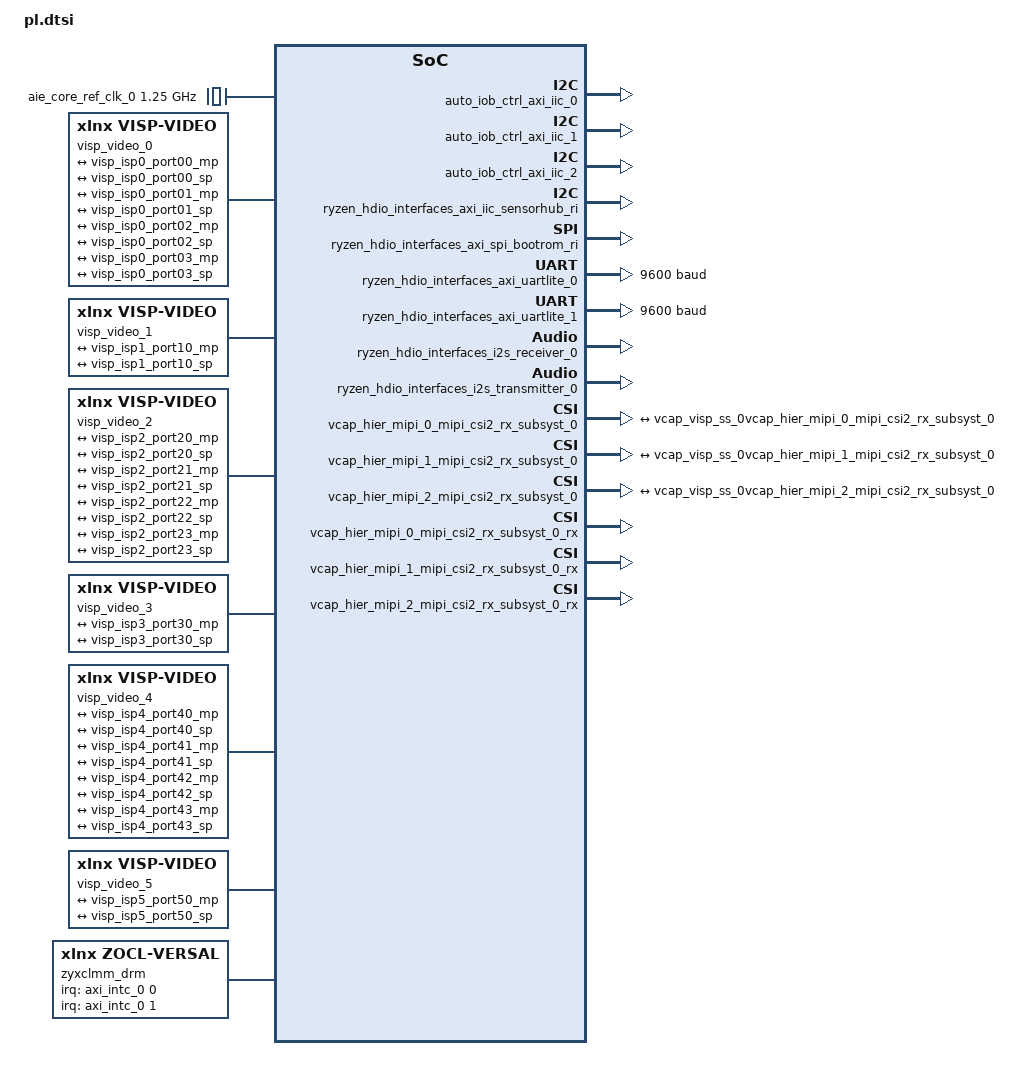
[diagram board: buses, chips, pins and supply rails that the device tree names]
/dts-v1/;
/plugin/;
&fpga {
	firmware-name = "vpl_gen_fixed_pld.pdi";
	misc_clk_3: misc_clk_3 {
		compatible = "fixed-clock";
		clock-frequency = <149998505>;
		#clock-cells = <0>;
	};
	misc_clk_4: misc_clk_4 {
		compatible = "fixed-clock";
		clock-frequency = <100000000>;
		#clock-cells = <0>;
	};
	misc_clk_2: misc_clk_2 {
		compatible = "fixed-clock";
		clock-frequency = <199998000>;
		#clock-cells = <0>;
	};
	misc_clk_6: misc_clk_6 {
		compatible = "fixed-clock";
		clock-frequency = <125000000>;
		#clock-cells = <0>;
	};
	misc_clk_0: misc_clk_0 {
		compatible = "fixed-clock";
		clock-frequency = <99999000>;
		#clock-cells = <0>;
	};
	misc_clk_5: misc_clk_5 {
		compatible = "fixed-clock";
		clock-frequency = <133332001>;
		#clock-cells = <0>;
	};
	misc_clk_1: misc_clk_1 {
		compatible = "fixed-clock";
		clock-frequency = <249997500>;
		#clock-cells = <0>;
	};
};

&amba {
	axi_intc_0: interrupt-controller@b01b0000 {
		#interrupt-cells = <2>;
		interrupts = < 0 143 4 >;
		xlnx,sense-of-irq-edge-type = "Rising";
		xlnx,edk-special = "INTR_CTRL";
		xlnx,kind-of-intr = <0xffe38>;
		xlnx,kind-of-edge = <0xffffffff>;
		xlnx,irq-is-level = <1>;
		xlnx,has-ivr = <1>;
		compatible = "xlnx,axi-intc-4.1" , "xlnx,xps-intc-1.00.a";
		xlnx,disable-synchronizers = <0>;
		xlnx,kind-of-lvl = <0xffffffff>;
		xlnx,ivar-reset-value = <0x10>;
		xlnx,irq-active = <0x1>;
		interrupt-parent = <&gic>;
		xlnx,en-cascade-mode = <0>;
		xlnx,ip-name = "axi_intc";
		xlnx,has-ilr = <0>;
		reg = <0x0 0xb01b0000 0x0 0x10000>;
		xlnx,addr-width = <0x20>;
		clocks = <&misc_clk_0>;
		xlnx,s-axi-aclk-freq-mhz = <0x5f5dd18>;
		xlnx,num-sw-intr = <0>;
		xlnx,irq-connection = <1>;
		xlnx,num-intr-inputs = <0x20>;
		xlnx,has-sie = <1>;
		xlnx,enable-async = <0>;
		xlnx,has-cie = <1>;
		xlnx,num-sync-ff = <2>;
		xlnx,edk-iptype = "PERIPHERAL";
		xlnx,mb-clk-not-connected = <1>;
		xlnx,has-ipr = <1>;
		xlnx,sense-of-irq-level-type = "Active_High";
		xlnx,cascade-master = <0>;
		xlnx,processor-clk-freq-mhz = <100>;
		xlnx,is-fast = <0x0>;
		clock-names = "s_axi_aclk";
		xlnx,has-fast = <0>;
		xlnx,ivar-rst-val = <0x10>;
		interrupt-controller;
		interrupt-names = "irq";
		xlnx,async-intr = <0xffcfffff>;
		xlnx,name = "axi_intc_0";
	};
	ai_engine_0: ai_engine@20000000000 {
		xlnx,num-mi-axi = <24>;
		compatible = "xlnx,ai-engine-2.0" , "xlnx,ai-engine-v2.0";
		xlnx,aie-ref-clk-freqmhz = <0x1fc9f08>;
		xlnx,num-mi-axis = <0>;
		xlnx,aie-max-freq = <1250>;
		xlnx,en-addr-virtualization = <0>;
		xlnx,aie-gen = /bits/ 8 <0x5>;
		xlnx,mem-rows = /bits/ 8 <1 1>;
		xlnx,mi-destid-pins;
		xlnx,ip-name = "ai_engine";
		#size-cells = <2>;
		xlnx,num-si-axi = <1>;
		xlnx,fast-pm-write;
		reg = <0x00000200 0x00000000 0x00000001 0x00000000>;
		clocks = <&aie_core_ref_clk_0>;
		xlnx,num-noc-axis-clks = <0>;
		ranges;
		xlnx,num-clks = <0>;
		xlnx,partition-enabled = <0>;
		#address-cells = <2>;
		xlnx,num-si-axis = <0>;
		xlnx,name-mi-axi = "M00_AXI";
		xlnx,num-column = <1>;
		xlnx,aie-core-ref-ctrl-freqmhz = <1250>;
		xlnx,clk-names = "aclk0";
		xlnx,fast-dm-write;
		xlnx,edk-iptype = "PERIPHERAL";
		xlnx,selected-nsu = <0>;
		clock-names = "aclk0";
		power-domains = <&versal2_firmware 0x18800000>;
		xlnx,num-trig-in = <0>;
		xlnx,en-ext-rst = <1>;
		xlnx,num-trig-out = <0>;
		xlnx,core-rows = /bits/ 8 <2 4>;
		xlnx,shim-rows = /bits/ 8 <0 1>;
		xlnx,name-si-axi = "S00_AXI";
		xlnx,start-column = <0>;
		xlnx,name = "ai_engine_0";
		xlnx,aie-site = "AIE2PS";
		aie_aperture_0: aie_aperture@20000000000 {
			xlnx,device-name = <0>;
			interrupt-parent = <&gic>;
			interrupts = <0x0 0xce 0x4>, <0x0 0xcf 0x4>, <0x0 0xd0 0x4>;
			#address-cells = <2>;
			power-domains = <&versal2_firmware 0x18800000>;
			xlnx,node-id = <0x18800000>;
			#size-cells = <2>;
			interrupt-names = "interrupt1" , "interrupt2" , "interrupt3";
			reg = <0x00000200 0x00000000 0x00000001 0x00000000>;
			xlnx,columns = < 0 24 >;
		};
	};
	auto_iob_ctrl_axi_gpio_0: gpio@b0130000 {
		xlnx,gpio-board-interface = "Custom";
		compatible = "xlnx,axi-gpio-2.0" , "xlnx,xps-gpio-1.00.a";
		xlnx,all-outputs = <0>;
		#gpio-cells = <2>;
		xlnx,gpio-width = <24>;
		xlnx,dout-default = <0x24042>;
		xlnx,is-dual = <0>;
		xlnx,ip-name = "axi_gpio";
		xlnx,tri-default-2 = <0xffffffff>;
		reg = <0x0 0xb0130000 0x0 0x10000>;
		xlnx,all-inputs-2 = <0>;
		clocks = <&misc_clk_0>;
		xlnx,all-outputs-2 = <0>;
		gpio-controller;
		xlnx,interrupt-present = <0>;
		xlnx,gpio2-board-interface = "Custom";
		xlnx,edk-iptype = "PERIPHERAL";
		xlnx,dout-default-2 = <0x0>;
		xlnx,gpio2-width = <32>;
		clock-names = "s_axi_aclk";
		xlnx,tri-default = <0xf00>;
		xlnx,name = "auto_iob_ctrl_axi_gpio_0";
		xlnx,all-inputs = <0>;
	};
	auto_iob_ctrl_axi_gpio_1: gpio@b0140000 {
		xlnx,gpio-board-interface = "Custom";
		compatible = "xlnx,axi-gpio-2.0" , "xlnx,xps-gpio-1.00.a";
		xlnx,all-outputs = <0>;
		#gpio-cells = <2>;
		xlnx,gpio-width = <5>;
		xlnx,dout-default = <0x0>;
		xlnx,is-dual = <0>;
		xlnx,ip-name = "axi_gpio";
		xlnx,tri-default-2 = <0xffffffff>;
		reg = <0x0 0xb0140000 0x0 0x10000>;
		xlnx,all-inputs-2 = <0>;
		clocks = <&misc_clk_0>;
		xlnx,all-outputs-2 = <0>;
		gpio-controller;
		xlnx,interrupt-present = <0>;
		xlnx,gpio2-board-interface = "Custom";
		xlnx,edk-iptype = "PERIPHERAL";
		xlnx,dout-default-2 = <0x0>;
		xlnx,gpio2-width = <32>;
		clock-names = "s_axi_aclk";
		xlnx,tri-default = <0xffffffff>;
		xlnx,name = "auto_iob_ctrl_axi_gpio_1";
		xlnx,all-inputs = <0>;
	};
	auto_iob_ctrl_axi_gpio_2: gpio@b0150000 {
		xlnx,gpio-board-interface = "Custom";
		compatible = "xlnx,axi-gpio-2.0" , "xlnx,xps-gpio-1.00.a";
		xlnx,all-outputs = <0>;
		#gpio-cells = <2>;
		xlnx,gpio-width = <5>;
		xlnx,dout-default = <0x0>;
		xlnx,is-dual = <0>;
		xlnx,ip-name = "axi_gpio";
		xlnx,tri-default-2 = <0xffffffff>;
		reg = <0x0 0xb0150000 0x0 0x10000>;
		xlnx,all-inputs-2 = <0>;
		clocks = <&misc_clk_0>;
		xlnx,all-outputs-2 = <0>;
		gpio-controller;
		xlnx,interrupt-present = <0>;
		xlnx,gpio2-board-interface = "Custom";
		xlnx,edk-iptype = "PERIPHERAL";
		xlnx,dout-default-2 = <0x0>;
		xlnx,gpio2-width = <32>;
		clock-names = "s_axi_aclk";
		xlnx,tri-default = <0xffffffff>;
		xlnx,name = "auto_iob_ctrl_axi_gpio_2";
		xlnx,all-inputs = <0>;
	};
	auto_iob_ctrl_axi_gpio_3: gpio@b0160000 {
		xlnx,gpio-board-interface = "Custom";
		compatible = "xlnx,axi-gpio-2.0" , "xlnx,xps-gpio-1.00.a";
		xlnx,all-outputs = <0>;
		#gpio-cells = <2>;
		xlnx,gpio-width = <6>;
		xlnx,dout-default = <0x0>;
		xlnx,is-dual = <0>;
		xlnx,ip-name = "axi_gpio";
		xlnx,tri-default-2 = <0xffffffff>;
		reg = <0x0 0xb0160000 0x0 0x10000>;
		xlnx,all-inputs-2 = <0>;
		clocks = <&misc_clk_0>;
		xlnx,all-outputs-2 = <0>;
		gpio-controller;
		xlnx,interrupt-present = <0>;
		xlnx,gpio2-board-interface = "Custom";
		xlnx,edk-iptype = "PERIPHERAL";
		xlnx,dout-default-2 = <0x0>;
		xlnx,gpio2-width = <32>;
		clock-names = "s_axi_aclk";
		xlnx,tri-default = <0xffffffff>;
		xlnx,name = "auto_iob_ctrl_axi_gpio_3";
		xlnx,all-inputs = <0>;
	};
	auto_iob_ctrl_axi_iic_0: i2c@80000000 {
		interrupts = < 0 90 4 >;
		xlnx,iic-freq-khz = <100>;
		compatible = "xlnx,axi-iic-2.1" , "xlnx,xps-iic-2.00.a";
		xlnx,scl-inertial-delay = <0>;
		interrupt-parent = <&gic>;
		xlnx,ip-name = "axi_iic";
		xlnx,disable-setup-violation-check = <0>;
		reg = <0x0 0x80000000 0x0 0x10000>;
		clocks = <&misc_clk_0>;
		xlnx,gpo-width = <1>;
		xlnx,edk-iptype = "PERIPHERAL";
		xlnx,static-timing-reg-width = <0>;
		xlnx,sda-level = <1>;
		clock-names = "s_axi_aclk";
		xlnx,ten-bit-adr = <0>;
		xlnx,default-value = <0x0>;
		interrupt-names = "iic2intc_irpt";
		xlnx,iic-board-interface = "Custom";
		xlnx,timing-reg-width = <32>;
		xlnx,iic-freq = <100000>;
		xlnx,smbus-pmbus-host = <0>;
		xlnx,name = "auto_iob_ctrl_axi_iic_0";
		xlnx,axi-aclk-freq-mhz = <0x5f5dd18>;
		xlnx,sda-inertial-delay = <0>;
	};
	auto_iob_ctrl_axi_iic_1: i2c@80010000 {
		interrupts = < 0 88 4 >;
		xlnx,iic-freq-khz = <100>;
		compatible = "xlnx,axi-iic-2.1" , "xlnx,xps-iic-2.00.a";
		xlnx,scl-inertial-delay = <0>;
		interrupt-parent = <&gic>;
		xlnx,ip-name = "axi_iic";
		xlnx,disable-setup-violation-check = <0>;
		reg = <0x0 0x80010000 0x0 0x10000>;
		clocks = <&misc_clk_0>;
		xlnx,gpo-width = <1>;
		xlnx,edk-iptype = "PERIPHERAL";
		xlnx,static-timing-reg-width = <0>;
		xlnx,sda-level = <1>;
		clock-names = "s_axi_aclk";
		xlnx,ten-bit-adr = <0>;
		xlnx,default-value = <0x0>;
		interrupt-names = "iic2intc_irpt";
		xlnx,iic-board-interface = "Custom";
		xlnx,timing-reg-width = <32>;
		xlnx,iic-freq = <100000>;
		xlnx,smbus-pmbus-host = <0>;
		xlnx,name = "auto_iob_ctrl_axi_iic_1";
		xlnx,axi-aclk-freq-mhz = <0x5f5dd18>;
		xlnx,sda-inertial-delay = <0>;
	};
	auto_iob_ctrl_axi_iic_2: i2c@80020000 {
		interrupts = < 0 89 4 >;
		xlnx,iic-freq-khz = <100>;
		compatible = "xlnx,axi-iic-2.1" , "xlnx,xps-iic-2.00.a";
		xlnx,scl-inertial-delay = <0>;
		interrupt-parent = <&gic>;
		xlnx,ip-name = "axi_iic";
		xlnx,disable-setup-violation-check = <0>;
		reg = <0x0 0x80020000 0x0 0x10000>;
		clocks = <&misc_clk_0>;
		xlnx,gpo-width = <1>;
		xlnx,edk-iptype = "PERIPHERAL";
		xlnx,static-timing-reg-width = <0>;
		xlnx,sda-level = <1>;
		clock-names = "s_axi_aclk";
		xlnx,ten-bit-adr = <0>;
		xlnx,default-value = <0x0>;
		interrupt-names = "iic2intc_irpt";
		xlnx,iic-board-interface = "Custom";
		xlnx,timing-reg-width = <32>;
		xlnx,iic-freq = <100000>;
		xlnx,smbus-pmbus-host = <0>;
		xlnx,name = "auto_iob_ctrl_axi_iic_2";
		xlnx,axi-aclk-freq-mhz = <0x5f5dd18>;
		xlnx,sda-inertial-delay = <0>;
	};
	axi_bram_ctrl_mdb5_v4l2: axi_bram_ctrl_mdb5_v4l2@80000008000 {
		xlnx,protocol = "AXI4";
		xlnx,edk-special = "BRAM_CTRL";
		compatible = "xlnx,axi-bram-ctrl-4.1" , "xlnx,axi-bram-ctrl";
		xlnx,ecc-onoff-reset-value = <0>;
		xlnx,ecc-type = <0>;
		xlnx,rd-cmd-optimization = <0>;
		xlnx,memory-depth = <2048>;
		xlnx,use-ecc = <0>;
		xlnx,fault-inject = <0>;
		xlnx,ip-name = "axi_bram_ctrl";
		reg = <0x00000800 0x00008000 0x0 0x2000>;
		xlnx,bmg-instance = "EXTERNAL";
		clocks = <&misc_clk_1>;
		xlnx,s-axi-ctrl-addr-width = <32>;
		xlnx,read-latency = <1>;
		xlnx,id-width = <0>;
		xlnx,s-axi-supports-narrow-burst = <0>;
		xlnx,supports-narrow-burst = <0>;
		xlnx,single-port-bram = <1>;
		xlnx,ecc = <0>;
		xlnx,edk-iptype = "PERIPHERAL";
		clock-names = "s_axi_aclk";
		xlnx,data-width = <32>;
		xlnx,bram-addr-width = <11>;
		xlnx,bram-inst-mode = "EXTERNAL";
		xlnx,s-axi-ctrl-data-width = <32>;
		xlnx,mem-depth = <2048>;
		xlnx,s-axi-id-width = <1>;
		xlnx,name = "axi_bram_ctrl_mdb5_v4l2";
	};
	axi_gpio_rst: gpio@b01a0000 {
		xlnx,gpio-board-interface = "Custom";
		compatible = "xlnx,axi-gpio-2.0" , "xlnx,xps-gpio-1.00.a";
		xlnx,all-outputs = <1>;
		#gpio-cells = <2>;
		xlnx,gpio-width = <32>;
		xlnx,dout-default = <0xffffffff>;
		xlnx,is-dual = <0>;
		xlnx,ip-name = "axi_gpio";
		xlnx,tri-default-2 = <0xffffffff>;
		reg = <0x0 0xb01a0000 0x0 0x10000>;
		xlnx,all-inputs-2 = <0>;
		clocks = <&misc_clk_0>;
		xlnx,all-outputs-2 = <0>;
		gpio-controller;
		xlnx,interrupt-present = <0>;
		xlnx,gpio2-board-interface = "Custom";
		xlnx,edk-iptype = "PERIPHERAL";
		xlnx,dout-default-2 = <0x0>;
		xlnx,gpio2-width = <32>;
		clock-names = "s_axi_aclk";
		xlnx,tri-default = <0xffffffff>;
		xlnx,name = "axi_gpio_rst";
		xlnx,all-inputs = <0>;
	};
	messaging_axi_bram_ctrl_0: messaging_axi_bram_ctrl_0@80100000000 {
		xlnx,protocol = "AXI4";
		xlnx,edk-special = "BRAM_CTRL";
		compatible = "xlnx,axi-bram-ctrl-4.1" , "xlnx,axi-bram-ctrl";
		xlnx,ecc-onoff-reset-value = <0>;
		xlnx,ecc-type = <0>;
		xlnx,rd-cmd-optimization = <0>;
		xlnx,memory-depth = <2048>;
		xlnx,use-ecc = <0>;
		xlnx,fault-inject = <0>;
		xlnx,ip-name = "axi_bram_ctrl";
		reg = <0x00000801 0x00000000 0x0 0x2000>;
		xlnx,bmg-instance = "EXTERNAL";
		clocks = <&misc_clk_0>;
		xlnx,s-axi-ctrl-addr-width = <32>;
		xlnx,read-latency = <1>;
		xlnx,id-width = <0>;
		xlnx,s-axi-supports-narrow-burst = <0>;
		xlnx,supports-narrow-burst = <0>;
		xlnx,single-port-bram = <1>;
		xlnx,ecc = <0>;
		xlnx,edk-iptype = "PERIPHERAL";
		clock-names = "s_axi_aclk";
		xlnx,data-width = <32>;
		xlnx,bram-addr-width = <11>;
		xlnx,bram-inst-mode = "EXTERNAL";
		xlnx,s-axi-ctrl-data-width = <32>;
		xlnx,mem-depth = <2048>;
		xlnx,s-axi-id-width = <1>;
		xlnx,name = "messaging_axi_bram_ctrl_0";
	};
	messaging_axi_bram_ctrl_1: messaging_axi_bram_ctrl_1@80100002000 {
		xlnx,protocol = "AXI4";
		xlnx,edk-special = "BRAM_CTRL";
		compatible = "xlnx,axi-bram-ctrl-4.1" , "xlnx,axi-bram-ctrl";
		xlnx,ecc-onoff-reset-value = <0>;
		xlnx,ecc-type = <0>;
		xlnx,rd-cmd-optimization = <0>;
		xlnx,memory-depth = <2048>;
		xlnx,use-ecc = <0>;
		xlnx,fault-inject = <0>;
		xlnx,ip-name = "axi_bram_ctrl";
		reg = <0x00000801 0x00002000 0x0 0x2000>;
		xlnx,bmg-instance = "EXTERNAL";
		clocks = <&misc_clk_0>;
		xlnx,s-axi-ctrl-addr-width = <32>;
		xlnx,read-latency = <1>;
		xlnx,id-width = <0>;
		xlnx,s-axi-supports-narrow-burst = <0>;
		xlnx,supports-narrow-burst = <0>;
		xlnx,single-port-bram = <1>;
		xlnx,ecc = <0>;
		xlnx,edk-iptype = "PERIPHERAL";
		clock-names = "s_axi_aclk";
		xlnx,data-width = <32>;
		xlnx,bram-addr-width = <11>;
		xlnx,bram-inst-mode = "EXTERNAL";
		xlnx,s-axi-ctrl-data-width = <32>;
		xlnx,mem-depth = <2048>;
		xlnx,s-axi-id-width = <1>;
		xlnx,name = "messaging_axi_bram_ctrl_1";
	};
	messaging_axi_gpio_0: gpio@80100005000 {
		xlnx,gpio-board-interface = "Custom";
		compatible = "xlnx,axi-gpio-2.0" , "xlnx,xps-gpio-1.00.a";
		xlnx,all-outputs = <1>;
		#gpio-cells = <2>;
		xlnx,gpio-width = <2>;
		xlnx,dout-default = <0x0>;
		xlnx,is-dual = <0>;
		xlnx,ip-name = "axi_gpio";
		xlnx,tri-default-2 = <0xffffffff>;
		reg = <0x00000801 0x00005000 0x0 0x1000>;
		xlnx,all-inputs-2 = <0>;
		clocks = <&misc_clk_0>;
		xlnx,all-outputs-2 = <0>;
		gpio-controller;
		xlnx,interrupt-present = <0>;
		xlnx,gpio2-board-interface = "Custom";
		xlnx,edk-iptype = "PERIPHERAL";
		xlnx,dout-default-2 = <0x0>;
		xlnx,gpio2-width = <32>;
		clock-names = "s_axi_aclk";
		xlnx,tri-default = <0xffffffff>;
		xlnx,name = "messaging_axi_gpio_0";
		xlnx,all-inputs = <0>;
	};
	messaging_axi_gpio_1: gpio@80100004000 {
		xlnx,gpio-board-interface = "Custom";
		compatible = "xlnx,axi-gpio-2.0" , "xlnx,xps-gpio-1.00.a";
		xlnx,all-outputs = <1>;
		#gpio-cells = <2>;
		xlnx,gpio-width = <2>;
		xlnx,dout-default = <0x0>;
		xlnx,is-dual = <0>;
		xlnx,ip-name = "axi_gpio";
		xlnx,tri-default-2 = <0xffffffff>;
		reg = <0x00000801 0x00004000 0x0 0x1000>;
		xlnx,all-inputs-2 = <0>;
		clocks = <&misc_clk_0>;
		xlnx,all-outputs-2 = <0>;
		gpio-controller;
		xlnx,interrupt-present = <0>;
		xlnx,gpio2-board-interface = "Custom";
		xlnx,edk-iptype = "PERIPHERAL";
		xlnx,dout-default-2 = <0x0>;
		xlnx,gpio2-width = <32>;
		clock-names = "s_axi_aclk";
		xlnx,tri-default = <0xffffffff>;
		xlnx,name = "messaging_axi_gpio_1";
		xlnx,all-inputs = <0>;
	};
	ryzen_hdio_interfaces_axi_gpio_0: gpio@b01c0000 {
		xlnx,gpio-board-interface = "Custom";
		compatible = "xlnx,axi-gpio-2.0" , "xlnx,xps-gpio-1.00.a";
		xlnx,all-outputs = <0>;
		#gpio-cells = <2>;
		xlnx,gpio-width = <2>;
		xlnx,dout-default = <0x0>;
		xlnx,is-dual = <0>;
		xlnx,ip-name = "axi_gpio";
		xlnx,tri-default-2 = <0xffffffff>;
		reg = <0x0 0xb01c0000 0x0 0x10000>;
		xlnx,all-inputs-2 = <0>;
		clocks = <&misc_clk_0>;
		xlnx,all-outputs-2 = <0>;
		gpio-controller;
		xlnx,interrupt-present = <0>;
		xlnx,gpio2-board-interface = "Custom";
		xlnx,edk-iptype = "PERIPHERAL";
		xlnx,dout-default-2 = <0x0>;
		xlnx,gpio2-width = <32>;
		clock-names = "s_axi_aclk";
		xlnx,tri-default = <0xffffffff>;
		xlnx,name = "ryzen_hdio_interfaces_axi_gpio_0";
		xlnx,all-inputs = <0>;
	};
	ryzen_hdio_interfaces_axi_gpio_bootrom_ri: gpio@b01d0000 {
		xlnx,gpio-board-interface = "Custom";
		compatible = "xlnx,axi-gpio-2.0" , "xlnx,xps-gpio-1.00.a";
		xlnx,all-outputs = <0>;
		#gpio-cells = <2>;
		xlnx,gpio-width = <1>;
		xlnx,dout-default = <0x0>;
		xlnx,is-dual = <0>;
		xlnx,ip-name = "axi_gpio";
		xlnx,tri-default-2 = <0xffffffff>;
		reg = <0x0 0xb01d0000 0x0 0x10000>;
		xlnx,all-inputs-2 = <0>;
		clocks = <&misc_clk_0>;
		xlnx,all-outputs-2 = <0>;
		gpio-controller;
		xlnx,interrupt-present = <0>;
		xlnx,gpio2-board-interface = "Custom";
		xlnx,edk-iptype = "PERIPHERAL";
		xlnx,dout-default-2 = <0x0>;
		xlnx,gpio2-width = <32>;
		clock-names = "s_axi_aclk";
		xlnx,tri-default = <0xffffffff>;
		xlnx,name = "ryzen_hdio_interfaces_axi_gpio_bootrom_ri";
		xlnx,all-inputs = <0>;
	};
	ryzen_hdio_interfaces_axi_gpio_sensorhub_ri: gpio@b01e0000 {
		xlnx,gpio-board-interface = "Custom";
		compatible = "xlnx,axi-gpio-2.0" , "xlnx,xps-gpio-1.00.a";
		xlnx,all-outputs = <0>;
		#gpio-cells = <2>;
		xlnx,gpio-width = <1>;
		xlnx,dout-default = <0x0>;
		xlnx,is-dual = <0>;
		xlnx,ip-name = "axi_gpio";
		xlnx,tri-default-2 = <0xffffffff>;
		reg = <0x0 0xb01e0000 0x0 0x10000>;
		xlnx,all-inputs-2 = <0>;
		clocks = <&misc_clk_0>;
		xlnx,all-outputs-2 = <0>;
		gpio-controller;
		xlnx,interrupt-present = <0>;
		xlnx,gpio2-board-interface = "Custom";
		xlnx,edk-iptype = "PERIPHERAL";
		xlnx,dout-default-2 = <0x0>;
		xlnx,gpio2-width = <32>;
		clock-names = "s_axi_aclk";
		xlnx,tri-default = <0xffffffff>;
		xlnx,name = "ryzen_hdio_interfaces_axi_gpio_sensorhub_ri";
		xlnx,all-inputs = <0>;
	};
	ryzen_hdio_interfaces_axi_iic_sensorhub_ri: i2c@b01f0000 {
		xlnx,iic-freq-khz = <100>;
		compatible = "xlnx,axi-iic-2.1" , "xlnx,xps-iic-2.00.a";
		xlnx,scl-inertial-delay = <0>;
		xlnx,ip-name = "axi_iic";
		xlnx,disable-setup-violation-check = <0>;
		reg = <0x0 0xb01f0000 0x0 0x10000>;
		clocks = <&misc_clk_0>;
		xlnx,gpo-width = <1>;
		xlnx,edk-iptype = "PERIPHERAL";
		xlnx,static-timing-reg-width = <0>;
		xlnx,sda-level = <1>;
		clock-names = "s_axi_aclk";
		xlnx,ten-bit-adr = <0>;
		xlnx,default-value = <0x0>;
		xlnx,iic-board-interface = "Custom";
		xlnx,timing-reg-width = <32>;
		xlnx,iic-freq = <100000>;
		xlnx,smbus-pmbus-host = <0>;
		xlnx,name = "ryzen_hdio_interfaces_axi_iic_sensorhub_ri";
		xlnx,axi-aclk-freq-mhz = <0x5f5dd18>;
		xlnx,sda-inertial-delay = <0>;
	};
	ryzen_hdio_interfaces_axi_spi_bootrom_ri: axi_quad_spi@b0210000 {
		xlnx,select-xpm = <0>;
		compatible = "xlnx,axi-quad-spi-3.2" , "xlnx,xps-spi-2.00.a";
		xlnx,lsb-stup = <0>;
		xlnx,num-ss-bits = <0x1>;
		xlnx,hasfifos = <1>;
		xlnx,xip-mode = <0>;
		xlnx,use-startup-ext = <0>;
		xlnx,s-axi4-addr-width = <24>;
		xlnx,byte-level-interrupt-en = <0>;
		num-cs = <0x1>;
		xlnx,xip-perf-mode = <1>;
		xlnx,sck-ratio = <16>;
		xlnx,s-axi4-id-width = <4>;
		fifo-size = <16>;
		xlnx,multiples16 = <1>;
		xlnx,master-mode = <1>;
		xlnx,shared-startup = <0>;
		xlnx,ip-name = "axi_quad_spi";
		xlnx,qspi-board-interface = "Custom";
		reg = <0x0 0xb0210000 0x0 0x10000>;
		xlnx,dual-quad-mode = <0>;
		xlnx,new-seq-en = <1>;
		bits-per-word = <8>;
		clocks = <&misc_clk_0>, <&misc_clk_0>;
		xlnx,num-transfer-bits = <8>;
		xlnx,spi-memory = <1>;
		xlnx,s-axi4-data-width = <32>;
		xlnx,edk-iptype = "PERIPHERAL";
		xlnx,slaveonly = <0>;
		xlnx,use-startup-int = <0>;
		xlnx,use-startup = <0>;
		xlnx,type-of-axi4-interface = <0>;
		xlnx,async-clk = <0>;
		xlnx,spi-mode = <0>;
		xlnx,sck-ratio1 = <1>;
		xlnx,fifo-depth = <16>;
		clock-names = "ext_spi_clk" , "s_axi_aclk";
		xlnx,uc-family = <0>;
		xlnx,spi-mem-addr-bits = <24>;
		xlnx,axi-interface = <0>;
		xlnx,Axi4-address = <0>;
		xlnx,fifo-included = <1>;
		xlnx,sub-family = "versal";
		xlnx,name = "ryzen_hdio_interfaces_axi_spi_bootrom_ri";
	};
	ryzen_hdio_interfaces_axi_uartlite_0: serial@b0220000 {
		compatible = "xlnx,axi-uartlite-2.0" , "xlnx,xps-uartlite-1.00.a";
		xlnx,uartlite-board-interface = "Custom";
		xlnx,s-axi-aclk-freq-hz-d = <0x5f5dd18>;
		xlnx,ip-name = "axi_uartlite";
		reg = <0x0 0xb0220000 0x0 0x10000>;
		xlnx,baudrate = <9600>;
		clocks = <&misc_clk_0>;
		current-speed = <9600>;
		xlnx,use-parity = <0>;
		xlnx,edk-iptype = "PERIPHERAL";
		xlnx,odd-parity = <0>;
		clock-names = "s_axi_aclk";
		xlnx,name = "ryzen_hdio_interfaces_axi_uartlite_0";
		xlnx,data-bits = <8>;
		xlnx,parity = "No_Parity";
	};
	ryzen_hdio_interfaces_axi_uartlite_1: serial@b0230000 {
		compatible = "xlnx,axi-uartlite-2.0" , "xlnx,xps-uartlite-1.00.a";
		xlnx,uartlite-board-interface = "Custom";
		xlnx,s-axi-aclk-freq-hz-d = <0x5f5dd18>;
		xlnx,ip-name = "axi_uartlite";
		reg = <0x0 0xb0230000 0x0 0x10000>;
		xlnx,baudrate = <9600>;
		clocks = <&misc_clk_0>;
		current-speed = <9600>;
		xlnx,use-parity = <0>;
		xlnx,edk-iptype = "PERIPHERAL";
		xlnx,odd-parity = <0>;
		clock-names = "s_axi_aclk";
		xlnx,name = "ryzen_hdio_interfaces_axi_uartlite_1";
		xlnx,data-bits = <8>;
		xlnx,parity = "No_Parity";
	};
	ryzen_hdio_interfaces_i2s_receiver_0: i2s_receiver@b0010000 {
		aud_mclk = <99999000>;
		interrupts = < 11 2 >;
		compatible = "xlnx,i2s-receiver-1.0" , "xlnx,i2s-receiver-1.0";
		xlnx,dwidth = <0x18>;
		xlnx,depth = <0x80>;
		interrupt-parent = <&axi_intc_0>;
		xlnx,ip-name = "i2s_receiver";
		reg = <0x0 0xb0010000 0x0 0x10000>;
		clocks = <&misc_clk_0>, <&misc_clk_0>, <&misc_clk_0>;
		xlnx,num-channels = <0x1>;
		xlnx,i2srx-board-interface = "Custom";
		xlnx,edk-iptype = "PERIPHERAL";
		xlnx,is-master = <1>;
		clock-names = "aud_mclk" , "m_axis_aud_aclk" , "s_axi_ctrl_aclk";
		xlnx,32bit-lr = <0>;
		interrupt-names = "irq";
		xlnx,name = "ryzen_hdio_interfaces_i2s_receiver_0";
	};
	ryzen_hdio_interfaces_i2s_transmitter_0: i2s_transmitter@b0020000 {
		aud_mclk = <99999000>;
		interrupts = < 12 2 >;
		compatible = "xlnx,i2s-transmitter-1.0" , "xlnx,i2s-transmitter-1.0";
		xlnx,dwidth = <0x18>;
		xlnx,depth = <0x80>;
		interrupt-parent = <&axi_intc_0>;
		xlnx,ip-name = "i2s_transmitter";
		reg = <0x0 0xb0020000 0x0 0x10000>;
		clocks = <&misc_clk_0>, <&misc_clk_0>, <&misc_clk_0>;
		xlnx,num-channels = <0x1>;
		xlnx,edk-iptype = "PERIPHERAL";
		xlnx,is-master = <1>;
		xlnx,i2stx-board-interface = "Custom";
		clock-names = "aud_mclk" , "s_axi_ctrl_aclk" , "s_axis_aud_aclk";
		xlnx,32bit-lr = <0>;
		interrupt-names = "irq";
		xlnx,name = "ryzen_hdio_interfaces_i2s_transmitter_0";
	};
	vcap_hier_mipi_0_mipi_csi2_rx_subsyst_0: mipi_csi2_rx_subsystem@b0040000 {
		xlnx,data-lane2-byte = "All_Byte";
		xlnx,dpy-en-reg-if = <1>;
		xlnx,cmn-vc = <4>;
		xlnx,dphy-lanes = <4>;
		xlnx,ip-name = "mipi_csi2_rx_subsystem";
		reg = <0x0 0xb0040000 0x0 0x2000>;
		xlnx,vfb-tu-width = <1>;
		xlnx,ppc = <4>;
		xlnx,csi-buf-depth = <4096>;
		xlnx,exdes-fmc = "LI-IMX274MIPI-FMC , V1.0 , Single , Sensor";
		xlnx,supportlevel = <1>;
		xlnx,clk-lane-io-loc-name = "None";
		xlnx,max-lanes = <4>;
		xlnx,is-versal;
		xlnx,cmn-inc-iic = <0>;
		xlnx,clk-lane-io-loc = "None";
		xlnx,esc-timeout = <25600>;
		interrupt-names = "csirxss_csi_irq";
		xlnx,cmn-inc-vfb;
		xlnx,axis-tuser-width = <96>;
		compatible = "xlnx,mipi-csi2-rx-subsystem-6.0" , "xlnx,mipi-csi2-rx-subsystem-5.0";
		xlnx,en-active-lanes;
		xlnx,idly-tap = <1>;
		dphy-present = <0>;
		xlnx,cmn-num-pixels = <4>;
		xlnx,cmn-proj-family = <0>;
		xlnx,csi2rx-dbg = <0>;
		xlnx,fifo-rd-en-control;
		xlnx,vfb;
		interrupt-parent = <&axi_intc_0>;
		xlnx,data-lane1-io-loc-name = "None";
		xlnx,hs-timeout = <65541>;
		xlnx,data-lane3-io-loc-name = "None";
		xlnx,ext-mmcm = <0>;
		xlnx,data-lane1-byte = "All_Byte";
		xlnx,master-riu;
		xlnx,cal-mode = "NONE";
		xlnx,csi-filter-userdatatype;
		rxphy-connected = <&vcap_hier_mipi_0_mipi_csi2_rx_subsyst_0_phy>;
		xlnx,mipi-rx-phy-mode = <1>;
		xlnx,data-lane0-io-position = <2>;
		xlnx,exdes-board = "VEK280";
		xlnx,data-lane2-io-position = <6>;
		xlnx,vc = <4>;
		xlnx,en-vcx = <0>;
		xlnx,name = "vcap_hier_mipi_0_mipi_csi2_rx_subsyst_0";
		xlnx,csi-emb-non-img = <0>;
		interrupts = < 1 2 >;
		xlnx,dphyrx-board-interface = "Custom";
		xlnx,data-lane3-io-loc = "None";
		xlnx,clock-mask = <39>;
		xlnx,hs-settle-ns = <25>;
		clocks = <&misc_clk_2>, <&misc_clk_3>, <&misc_clk_3>;
		xlnx,data-lane2-io-loc = "None";
		xlnx,mipi-slv-int = <0>;
		xlnx,is-ksb;
		xlnx,cmn-fifo-rd-en-cntrl;
		xlnx,data-lane3-byte = "All_Byte";
		xlnx,stretch-line-rate = <4500>;
		xlnx,phy-mode = "DPHY";
		xlnx,axis-tdest-width = <4>;
		xlnx,en-csi-v2 = <0>;
		xlnx,edk-iptype = "PERIPHERAL";
		xlnx,init = <100000>;
		xlnx,cmn-pxl-format = <0x2c>;
		xlnx,int-qor-check = <0>;
		clock-names = "dphy_clk_200M" , "lite_aclk" , "video_aclk";
		xlnx,data-lane1-io-loc = "None";
		xlnx,data-lane0-byte = "All_Byte";
		xlnx,ooc-vid-clk = <0x65b710>;
		csirx-present = <1>;
		xlnx,yuv420-buf-dpth = <128>;
		xlnx,hp-io-bank-selection = <64>;
		xlnx,idly-group-name = "mipi_csi2rx_idly_group";
		xlnx,lprx-disable-extport = <0>;
		csirx-connected = <&vcap_hier_mipi_0_mipi_csi2_rx_subsyst_0_rx>;
		xlnx,highaddr = <0xb0041fff>;
		xlnx,cmn-num-lanes = <4>;
		xlnx,exdes-config = "MIPI_Video_Pipe_Camera_to_Display";
		xlnx,exdesboard-version = <2>;
		xlnx,dphy-preset = "CSI2RX_XLNX";
		xlnx,data-lane0-io-loc-name = "None";
		xlnx,csi-pxl-format = <0x2c>;
		xlnx,clk-lane-io-position = <0>;
		xlnx,data-lane2-io-loc-name = "None";
		xlnx,data-lane0-io-loc = "None";
		xlnx,inc-phy;
		xlnx,hs-line-rate = <800>;
		rxphy-present = <1>;
		xlnx,dpy-line-rate = <1500>;
		xlnx,csi-en-activelanes;
		xlnx,sprt-isp-bridge;
		xlnx,csi-en-crc = <1>;
		xlnx,axis-tdata-width = <32>;
		xlnx,csi-controller-reg-if;
		xlnx,data-lane1-io-position = <4>;
		xlnx,dphy-mode = "SLAVE";
		xlnx,data-lane3-io-position = <8>;
		mipi_csi_portsvcap_hier_mipi_0_mipi_csi2_rx_subsyst_0: ports {
			#address-cells = <1>;
			#size-cells = <0>;
			mipi_csi_port1vcap_hier_mipi_0_mipi_csi2_rx_subsyst_0: port@1 {
				xlnx,video-width = <8>;
				reg = <1>;
				xlnx,video-format = <12>;
				xlnx,cfa-pattern = "rggb";
				mipi_csirx_outvcap_hier_mipi_0_mipi_csi2_rx_subsyst_0: endpoint {
					remote-endpoint = <&vcap_visp_ss_0vcap_hier_mipi_0_mipi_csi2_rx_subsyst_0>;
				};
			};
			mipi_csi_port0vcap_hier_mipi_0_mipi_csi2_rx_subsyst_0: port@0 {
				xlnx,video-width = <8>;
				reg = <0>;
				xlnx,video-format = <12>;
				xlnx,cfa-pattern = "rggb";
				mipi_csi_invcap_hier_mipi_0_mipi_csi2_rx_subsyst_0: endpoint {
					data-lanes = < 1 2 3 4 >;
				};
			};
		};
	};
	vcap_hier_mipi_1_mipi_csi2_rx_subsyst_0: mipi_csi2_rx_subsystem@b0060000 {
		xlnx,data-lane2-byte = "All_Byte";
		xlnx,dpy-en-reg-if = <1>;
		xlnx,cmn-vc = <4>;
		xlnx,dphy-lanes = <4>;
		xlnx,ip-name = "mipi_csi2_rx_subsystem";
		reg = <0x0 0xb0060000 0x0 0x2000>;
		xlnx,vfb-tu-width = <1>;
		xlnx,ppc = <4>;
		xlnx,csi-buf-depth = <4096>;
		xlnx,exdes-fmc = "LI-IMX274MIPI-FMC , V1.0 , Single , Sensor";
		xlnx,supportlevel = <0>;
		xlnx,clk-lane-io-loc-name = "None";
		xlnx,max-lanes = <4>;
		xlnx,is-versal;
		xlnx,cmn-inc-iic = <0>;
		xlnx,clk-lane-io-loc = "None";
		xlnx,esc-timeout = <25600>;
		interrupt-names = "csirxss_csi_irq";
		xlnx,cmn-inc-vfb;
		xlnx,axis-tuser-width = <96>;
		compatible = "xlnx,mipi-csi2-rx-subsystem-6.0" , "xlnx,mipi-csi2-rx-subsystem-5.0";
		xlnx,en-active-lanes;
		xlnx,idly-tap = <1>;
		dphy-present = <0>;
		xlnx,cmn-num-pixels = <4>;
		xlnx,cmn-proj-family = <0>;
		xlnx,csi2rx-dbg = <0>;
		xlnx,fifo-rd-en-control;
		xlnx,vfb;
		interrupt-parent = <&axi_intc_0>;
		xlnx,data-lane1-io-loc-name = "None";
		xlnx,hs-timeout = <65541>;
		xlnx,data-lane3-io-loc-name = "None";
		xlnx,ext-mmcm = <0>;
		xlnx,data-lane1-byte = "All_Byte";
		xlnx,master-riu;
		xlnx,cal-mode = "NONE";
		xlnx,csi-filter-userdatatype;
		rxphy-connected = <&vcap_hier_mipi_1_mipi_csi2_rx_subsyst_0_phy>;
		xlnx,mipi-rx-phy-mode = <1>;
		xlnx,data-lane0-io-position = <2>;
		xlnx,exdes-board = "VEK280";
		xlnx,data-lane2-io-position = <6>;
		xlnx,vc = <4>;
		xlnx,en-vcx = <0>;
		xlnx,name = "vcap_hier_mipi_1_mipi_csi2_rx_subsyst_0";
		xlnx,csi-emb-non-img = <0>;
		interrupts = < 2 2 >;
		xlnx,dphyrx-board-interface = "Custom";
		xlnx,data-lane3-io-loc = "None";
		xlnx,clock-mask = <39>;
		xlnx,hs-settle-ns = <25>;
		clocks = <&misc_clk_4>, <&misc_clk_2>, <&misc_clk_3>, <&misc_clk_4>, <&misc_clk_3>;
		xlnx,data-lane2-io-loc = "None";
		xlnx,mipi-slv-int = <0>;
		xlnx,is-ksb;
		xlnx,cmn-fifo-rd-en-cntrl;
		xlnx,data-lane3-byte = "All_Byte";
		xlnx,stretch-line-rate = <4500>;
		xlnx,phy-mode = "DPHY";
		xlnx,axis-tdest-width = <4>;
		xlnx,en-csi-v2 = <0>;
		xlnx,edk-iptype = "PERIPHERAL";
		xlnx,init = <100000>;
		xlnx,cmn-pxl-format = <0x2c>;
		xlnx,int-qor-check = <0>;
		clock-names = "cnts_rxwordclkhs_in" , "dphy_clk_200M" , "lite_aclk" , "shared_pll_clkoutphy_in" , "video_aclk";
		xlnx,data-lane1-io-loc = "None";
		xlnx,data-lane0-byte = "All_Byte";
		xlnx,ooc-vid-clk = <0x65b710>;
		csirx-present = <1>;
		xlnx,yuv420-buf-dpth = <128>;
		xlnx,hp-io-bank-selection = <64>;
		xlnx,idly-group-name = "mipi_csi2rx_idly_group";
		xlnx,lprx-disable-extport = <0>;
		csirx-connected = <&vcap_hier_mipi_1_mipi_csi2_rx_subsyst_0_rx>;
		xlnx,highaddr = <0xb0061fff>;
		xlnx,cmn-num-lanes = <4>;
		xlnx,exdes-config = "MIPI_Video_Pipe_Camera_to_Display";
		xlnx,exdesboard-version = <2>;
		xlnx,dphy-preset = "CSI2RX_XLNX";
		xlnx,data-lane0-io-loc-name = "None";
		xlnx,csi-pxl-format = <0x2c>;
		xlnx,clk-lane-io-position = <0>;
		xlnx,data-lane2-io-loc-name = "None";
		xlnx,data-lane0-io-loc = "None";
		xlnx,inc-phy;
		xlnx,hs-line-rate = <800>;
		rxphy-present = <1>;
		xlnx,dpy-line-rate = <1500>;
		xlnx,csi-en-activelanes;
		xlnx,sprt-isp-bridge;
		xlnx,csi-en-crc = <1>;
		xlnx,axis-tdata-width = <32>;
		xlnx,csi-controller-reg-if;
		xlnx,data-lane1-io-position = <4>;
		xlnx,dphy-mode = "SLAVE";
		xlnx,data-lane3-io-position = <8>;
		mipi_csi_portsvcap_hier_mipi_1_mipi_csi2_rx_subsyst_0: ports {
			#address-cells = <1>;
			#size-cells = <0>;
			mipi_csi_port1vcap_hier_mipi_1_mipi_csi2_rx_subsyst_0: port@1 {
				xlnx,video-width = <8>;
				reg = <1>;
				xlnx,video-format = <12>;
				xlnx,cfa-pattern = "rggb";
				mipi_csirx_outvcap_hier_mipi_1_mipi_csi2_rx_subsyst_0: endpoint {
					remote-endpoint = <&vcap_visp_ss_0vcap_hier_mipi_1_mipi_csi2_rx_subsyst_0>;
				};
			};
			mipi_csi_port0vcap_hier_mipi_1_mipi_csi2_rx_subsyst_0: port@0 {
				xlnx,video-width = <8>;
				reg = <0>;
				xlnx,video-format = <12>;
				xlnx,cfa-pattern = "rggb";
				mipi_csi_invcap_hier_mipi_1_mipi_csi2_rx_subsyst_0: endpoint {
					data-lanes = < 1 2 3 4 >;
				};
			};
		};
	};
	vcap_hier_mipi_2_mipi_csi2_rx_subsyst_0: mipi_csi2_rx_subsystem@b0000000 {
		xlnx,data-lane2-byte = "All_Byte";
		xlnx,dpy-en-reg-if = <1>;
		xlnx,cmn-vc = <4>;
		xlnx,dphy-lanes = <3>;
		xlnx,ip-name = "mipi_csi2_rx_subsystem";
		reg = <0x0 0xb0000000 0x0 0x2000>;
		xlnx,vfb-tu-width = <1>;
		xlnx,ppc = <4>;
		xlnx,csi-buf-depth = <4096>;
		xlnx,exdes-fmc = "LI-IMX274MIPI-FMC , V1.0 , Single , Sensor";
		xlnx,supportlevel = <1>;
		xlnx,clk-lane-io-loc-name = "None";
		xlnx,max-lanes = <3>;
		xlnx,is-versal;
		xlnx,cmn-inc-iic = <0>;
		xlnx,clk-lane-io-loc = "None";
		xlnx,esc-timeout = <25600>;
		interrupt-names = "csirxss_csi_irq";
		xlnx,cmn-inc-vfb;
		xlnx,axis-tuser-width = <96>;
		compatible = "xlnx,mipi-csi2-rx-subsystem-6.0" , "xlnx,mipi-csi2-rx-subsystem-5.0";
		xlnx,en-active-lanes;
		xlnx,idly-tap = <1>;
		dphy-present = <0>;
		xlnx,cmn-num-pixels = <4>;
		xlnx,cmn-proj-family = <0>;
		xlnx,csi2rx-dbg = <0>;
		xlnx,fifo-rd-en-control;
		xlnx,vfb;
		interrupt-parent = <&axi_intc_0>;
		xlnx,data-lane1-io-loc-name = "None";
		xlnx,hs-timeout = <65541>;
		xlnx,data-lane3-io-loc-name = "None";
		xlnx,ext-mmcm = <0>;
		xlnx,data-lane1-byte = "All_Byte";
		xlnx,master-riu;
		xlnx,cal-mode = "NONE";
		xlnx,csi-filter-userdatatype;
		rxphy-connected = <&vcap_hier_mipi_2_mipi_csi2_rx_subsyst_0_phy>;
		xlnx,mipi-rx-phy-mode = <0>;
		xlnx,data-lane0-io-position = <2>;
		xlnx,exdes-board = "VEK280";
		xlnx,data-lane2-io-position = <6>;
		xlnx,vc = <4>;
		xlnx,en-vcx = <0>;
		xlnx,name = "vcap_hier_mipi_2_mipi_csi2_rx_subsyst_0";
		xlnx,csi-emb-non-img = <0>;
		interrupts = < 0 2 >;
		xlnx,dphyrx-board-interface = "Custom";
		xlnx,data-lane3-io-loc = "None";
		xlnx,clock-mask = <39>;
		xlnx,hs-settle-ns = <16>;
		clocks = <&misc_clk_2>, <&misc_clk_3>, <&misc_clk_3>;
		xlnx,data-lane2-io-loc = "None";
		xlnx,mipi-slv-int = <0>;
		xlnx,is-ksb;
		xlnx,cmn-fifo-rd-en-cntrl;
		xlnx,data-lane3-byte = "All_Byte";
		xlnx,stretch-line-rate = <4500>;
		xlnx,phy-mode = "CPHY";
		xlnx,axis-tdest-width = <4>;
		xlnx,en-csi-v2 = <0>;
		xlnx,edk-iptype = "PERIPHERAL";
		xlnx,init = <100000>;
		xlnx,cmn-pxl-format = <0x2c>;
		xlnx,int-qor-check = <0>;
		clock-names = "dphy_clk_200M" , "lite_aclk" , "video_aclk";
		xlnx,data-lane1-io-loc = "None";
		xlnx,data-lane0-byte = "All_Byte";
		xlnx,ooc-vid-clk = <0x65b710>;
		csirx-present = <1>;
		xlnx,yuv420-buf-dpth = <128>;
		xlnx,hp-io-bank-selection = <64>;
		xlnx,idly-group-name = "mipi_csi2rx_idly_group";
		xlnx,lprx-disable-extport = <0>;
		csirx-connected = <&vcap_hier_mipi_2_mipi_csi2_rx_subsyst_0_rx>;
		xlnx,highaddr = <0xb0001fff>;
		xlnx,cmn-num-lanes = <3>;
		xlnx,exdes-config = "MIPI_Video_Pipe_Camera_to_Display";
		xlnx,exdesboard-version = <2>;
		xlnx,dphy-preset = "CSI2RX_XLNX";
		xlnx,data-lane0-io-loc-name = "None";
		xlnx,csi-pxl-format = <0x2c>;
		xlnx,clk-lane-io-position = <0>;
		xlnx,data-lane2-io-loc-name = "None";
		xlnx,data-lane0-io-loc = "None";
		xlnx,inc-phy;
		xlnx,hs-line-rate = <800>;
		rxphy-present = <1>;
		xlnx,dpy-line-rate = <1500>;
		xlnx,sprt-isp-bridge;
		xlnx,csi-en-crc = <1>;
		xlnx,axis-tdata-width = <32>;
		xlnx,csi-controller-reg-if;
		xlnx,data-lane1-io-position = <4>;
		xlnx,dphy-mode = "SLAVE";
		xlnx,data-lane3-io-position = <8>;
		mipi_csi_portsvcap_hier_mipi_2_mipi_csi2_rx_subsyst_0: ports {
			#address-cells = <1>;
			#size-cells = <0>;
			mipi_csi_port1vcap_hier_mipi_2_mipi_csi2_rx_subsyst_0: port@1 {
				xlnx,video-width = <8>;
				reg = <1>;
				xlnx,video-format = <12>;
				xlnx,cfa-pattern = "rggb";
				mipi_csirx_outvcap_hier_mipi_2_mipi_csi2_rx_subsyst_0: endpoint {
					remote-endpoint = <&vcap_visp_ss_0vcap_hier_mipi_2_mipi_csi2_rx_subsyst_0>;
				};
			};
			mipi_csi_port0vcap_hier_mipi_2_mipi_csi2_rx_subsyst_0: port@0 {
				xlnx,video-width = <8>;
				reg = <0>;
				xlnx,video-format = <12>;
				xlnx,cfa-pattern = "rggb";
				mipi_csi_invcap_hier_mipi_2_mipi_csi2_rx_subsyst_0: endpoint {
					data-lanes = < 1 2 3 >;
				};
			};
		};
	};
	vcu_vcu2_0: vcu2@b0030000 {
		xlnx,c0-debug-clk-enable = <0>;
		xlnx,c0-enc-source-format = <0>;
		xlnx,c0-lc-clkfbout-fract-b = <24>;
		xlnx,c0-hdl-decoder-en = <1>;
		xlnx,decoder-no-of-streams-1 = <1>;
		xlnx,c1-no-of-dec-streams = <1>;
		xlnx,c0-enc-mcu-and-core-clk = <950>;
		xlnx,c0-dec-video-standard = <0>;
		xlnx,ip-name = "vcu2";
		#size-cells = <2>;
		reg = <0x0 0xb0030000 0x0 0x10000 0x0 0xe8000000 0x0 0x100000>;
		xlnx,encoder-resolution = "4096X2160";
		xlnx,c1-axi-slave-clk = <167>;
		xlnx,c0-enable-seperate-interrupts;
		#address-cells = <2>;
		xlnx,decoder-frequency-1 = <1050>;
		xlnx,c1-debug-clk-enable = <0>;
		xlnx,actual-c1-dec-mcu-and-core-clk = <0x36b6ce30>;
		xlnx,decoder-color-depth = <12>;
		xlnx,c1-lc-clkin-period-a = <0x7270e0>;
		xlnx,c0-dec-coding-type = <0>;
		xlnx,c0-enc-fps = <3>;
		xlnx,c0-hdl-enable-encoder-jtag = <0>;
		xlnx,decoder-resolution-1 = "4096X2160";
		xlnx,c1-lc-clkin-period-b = <0x7270e0>;
		xlnx,c1-hdl-enable-encoder-jtag = <0>;
		xlnx,c1-enc-fps = <3>;
		xlnx,c1-enable-encoder;
		xlnx,c1-dec-coding-type = <0>;
		xlnx,decoder-color-format-1 = <444>;
		xlnx,c1-hdl-encoder-en = <1>;
		xlnx,c0-en-debug-clk;
		xlnx,c0-enable-encoder-jtag;
		interrupt-names = "c0_irq_dec_pintreq" , "c0_irq_enc_pintreq" , "c0_irq_error";
		xlnx,c0-enc-color-format = <3>;
		xlnx,c1-lc-clkout-divide2-a = <4>;
		xlnx,actual-c1-axi-slave-clk = <0x9f2b120>;
		xlnx,enable-instance1 = <0>;
		xlnx,c1-lc-divclk-divide-a = <2>;
		xlnx,c1-lc-clkout-divide2-b = <3>;
		compatible = "xlnx,vcu2-3.0";
		xlnx,c0-dec-color-depth = <2>;
		xlnx,encoder-frame-per-second-1 = <60>;
		xlnx,c1-lc-divclk-divide-b = <1>;
		xlnx,c1-enc-source-format = <0>;
		xlnx,c1-dec-color-depth = <2>;
		xlnx,c0-dec-mcu-and-core-clk = <918>;
		xlnx,actual-c0-enc-mcu-and-core-clk = <0x389f8b60>;
		xlnx,c0-enable-encoder;
		xlnx,decoder-frequency = <1050>;
		xlnx,c0-hdl-enc-enable-low-latency-mode = <0>;
		xlnx,c0-hdl-encoder-en = <1>;
		interrupt-parent = <&axi_intc_0>;
		xlnx,c1-hdl-enc-enable-low-latency-mode = <0>;
		xlnx,c0-no-of-enc-streams = <1>;
		xlnx,encoder-frequency = <950>;
		xlnx,encoder-coding-standard = "HEVC";
		xlnx,c1-dec-enable-low-latency-mode;
		xlnx,c0-enc-enable-low-latency-mode;
		xlnx,c0-enc-video-standard = <0>;
		xlnx,c1-enc-color-format = <3>;
		xlnx,c0-axi-slave-clk = <167>;
		xlnx,encoder-color-format = <444>;
		xlnx,c0-hdl-enable-decoder-jtag = <0>;
		xlnx,c1-hdl-enable-decoder-jtag = <0>;
		xlnx,c0-lc-clkfbout-mult-a = <55>;
		xlnx,new-param-for-image = <0>;
		xlnx,target-board = <0>;
		xlnx,c0-ref-clk = <0x7f27450>;
		xlnx,c0-lc-clkfbout-mult-b = <21>;
		xlnx,encoder-frame-per-second = <60>;
		xlnx,c1-ref-clk = <0x7f27450>;
		xlnx,c1-dec-frame-size = <5>;
		xlnx,c0-enable-decoder-jtag;
		xlnx,c0-dec-color-format = <3>;
		xlnx,num-of-instances = <0>;
		xlnx,c1-dec-video-standard = <0>;
		xlnx,encoder-color-format-1 = <444>;
		xlnx,actual-c0-axi-slave-clk = <0x9f2b120>;
		xlnx,name = "vcu_vcu2_0";
		interrupts = < 7 2 8 2 6 2 >;
		xlnx,enable-instance0-dpll;
		xlnx,c1-lc-clkout-divide3-a = <22>;
		xlnx,c1-lc-clkfbout-fract-a = <5>;
		xlnx,actual-c0-dec-mcu-and-core-clk = <0x36b6ce30>;
		xlnx,c1-lc-clkfbout-fract-b = <24>;
		xlnx,c1-enable-seperate-interrupts;
		xlnx,design-topology = <0>;
		xlnx,c0-dec-frame-size = <5>;
		xlnx,encoder-no-of-streams-1 = <1>;
		xlnx,c1-no-of-enc-streams = <1>;
		xlnx,c1-dec-color-format = <3>;
		xlnx,decoder-color-format = <444>;
		clocks = <&misc_clk_5>, <&misc_clk_0>;
		xlnx,c0-dec-fps = <3>;
		xlnx,decoder-frame-per-second = <60>;
		xlnx,decoder-coding-standard-1 = "HEVC";
		xlnx,c1-enable-decoder;
		xlnx,c1-dec-fps = <3>;
		xlnx,edk-iptype = "PERIPHERAL";
		xlnx,encoder-frequency-1 = <950>;
		xlnx,encoder-coding-standard-1 = "HEVC";
		xlnx,encoder-color-depth = <12>;
		xlnx,c1-enc-mcu-and-core-clk = <950>;
		xlnx,c0-enc-coding-type = <0>;
		clock-names = "dpll_ref_clk" , "s_axi_lite_clk";
		xlnx,c1-enc-frame-size = <5>;
		xlnx,c1-enc-coding-type = <0>;
		xlnx,c1-enable-encoder-jtag;
		xlnx,c0-lc-clkout-divide2-a = <4>;
		xlnx,c1-enc-video-standard = <0>;
		xlnx,c0-lc-clkout-divide2-b = <3>;
		xlnx,decoder-color-depth-1 = <12>;
		xlnx,c0-enable-decoder;
		xlnx,c0-hdl-dec-enable-low-latency-mode = <0>;
		xlnx,encoder-color-depth-1 = <12>;
		xlnx,c1-lc-clkfbout-mult-a = <55>;
		xlnx,c1-hdl-dec-enable-low-latency-mode = <0>;
		xlnx,c0-no-of-dec-streams = <1>;
		xlnx,c0-enc-color-depth = <2>;
		xlnx,decoder-coding-standard = "HEVC";
		xlnx,c1-lc-clkfbout-mult-b = <21>;
		xlnx,c1-enc-color-depth = <2>;
		xlnx,c0-dec-enable-low-latency-mode;
		xlnx,c0-enc-frame-size = <5>;
		xlnx,decoder-resolution = "4096X2160";
		xlnx,c1-en-debug-clk;
		xlnx,c1-enc-enable-low-latency-mode;
		xlnx,c0-lc-divclk-divide-a = <2>;
		xlnx,c0-lc-divclk-divide-b = <1>;
		xlnx,c0-lc-clkin-period-a = <0x7270e0>;
		xlnx,c1-hdl-decoder-en = <1>;
		xlnx,c1-dec-mcu-and-core-clk = <918>;
		xlnx,c0-lc-clkin-period-b = <0x7270e0>;
		xlnx,actual-c1-enc-mcu-and-core-clk = <0x389f8b60>;
		xlnx,decoder-no-of-streams = <1>;
		xlnx,c1-enable-decoder-jtag;
		xlnx,encoder-resolution-1 = "4096X2160";
		xlnx,encoder-no-of-streams = <1>;
		#clock-cells = <1>;
		xlnx,decoder-frame-per-second-1 = <60>;
		xlnx,c0-lc-clkout-divide3-a = <22>;
		xlnx,c0-lc-clkfbout-fract-a = <5>;
	};
	vcap_hier_mipi_0_mipi_csi2_rx_subsyst_0_phy: vcap_hier_mipi_0_mipi_csi2_rx_subsyst_0_phy@1000 {
		xlnx,en-csi-cnts-word-clk;
		xlnx,en-alp = <0>;
		xlnx,ip-name = "mipi_rx_phy";
		reg = <0x0 0xb0041000 0x0 0x1000>;
		xlnx,line-rate = <1500>;
		xlnx,max-symbols = <16>;
		xlnx,ppi-rxdwidth = <16>;
		xlnx,supportlevel;
		xlnx,alp-pause-wake-ulps = <50>;
		xlnx,esc-timeout = <25600>;
		xlnx,data-width = <32>;
		xlnx,lib-fifo = <1>;
		xlnx,ddr-clk-period = <0x145708>;
		xlnx,phy-lanes = <4>;
		compatible = "xlnx,mipi-rx-phy-1.0";
		xlnx,prbs-seed = <0000000000000001>;
		xlnx,en-preamble-seq = <0>;
		xlnx,hs-timeout = <65541>;
		xlnx,alp-pause-wake-stop = <4>;
		xlnx,ppi-v-width = <1>;
		xlnx,en-esc-mode = <0>;
		xlnx,wakeup = <200000>;
		xlnx,en-init-periodic-seq = <0>;
		xlnx,stb-width = <4>;
		xlnx,en-ulps-wakeup-cnt = <0>;
		xlnx,name = "vcap_hier_mipi_0_mipi_csi2_rx_subsyst_0_phy";
		xlnx,phy-preset = "CSI2RX_XLNX";
		xlnx,clock-mask = <39>;
		xlnx,addr-width = <8>;
		xlnx,is-hierarchy;
		clocks = <&misc_clk_2>, <&misc_clk_3>;
		xlnx,stable-clk-period = <200>;
		xlnx,phy-mode = <1>;
		xlnx,edk-iptype = "PERIPHERAL";
		xlnx,init-cntr-1 = <1024>;
		xlnx,en-alt-seq = <0>;
		xlnx,init-cntr-2 = <20>;
		clock-names = "core_clk" , "s_axi_aclk";
		xlnx,hs-settle = <25>;
		xlnx,esc-clk-period = <50>;
		xlnx,calib-en = <0>;
		xlnx,en-timeout-regs = <0>;
		xlnx,back2back-sync = <0>;
		xlnx,resp-width = <2>;
		xlnx,dbg-ports-on = <0>;
		xlnx,reg-on = <1>;
		xlnx,cts-en-phy-init = <0>;
	};
	vcap_hier_mipi_0_mipi_csi2_rx_subsyst_0_rx: vcap_hier_mipi_0_mipi_csi2_rx_subsyst_0_rx@0 {
		xlnx,ip-name = "mipi_csi2_rx_ctrl";
		reg = <0x0 0xb0040000 0x0 0x1000>;
		xlnx,ppi-sig-width = <1>;
		xlnx,cmn-inc-vfb;
		xlnx,axis-tuser-width = <112>;
		compatible = "xlnx,mipi-csi2-rx-ctrl-1.0";
		xlnx,cmn-num-pixels = <4>;
		xlnx,cmn-proj-family = <0>;
		xlnx,csi2rx-dbg = <0>;
		xlnx,csi-opt1-regs = <0>;
		xlnx,disable-lite = <0>;
		xlnx,ppi-sync-width = <0>;
		xlnx,csi-filter-userdatatype = <1>;
		xlnx,csi-offload-nonimage = <0>;
		xlnx,csi-vc-off-10 = <11>;
		xlnx,emb-dw = <96>;
		xlnx,csi-vc-off-11 = <12>;
		xlnx,csi-vc-off-12 = <13>;
		xlnx,csi-vc-off-13 = <14>;
		xlnx,csi-vc-off-14 = <15>;
		xlnx,ppi-mult = <1>;
		xlnx,name = "vcap_hier_mipi_0_mipi_csi2_rx_subsyst_0_rx";
		xlnx,en-vcx;
		xlnx,csi-vc-off-0 = <1>;
		xlnx,csi-vc-off-1 = <2>;
		xlnx,csi-vc-off-2 = <3>;
		xlnx,csi-vc-off-3 = <4>;
		xlnx,csi-vc-off-4 = <5>;
		xlnx,csi-lanes = <4>;
		xlnx,csi-vc-off-5 = <6>;
		xlnx,is-hierarchy;
		xlnx,axis-fifo-depth = <4096>;
		xlnx,csi-vc-off-6 = <7>;
		clocks = <&misc_clk_2>, <&misc_clk_4>, <&misc_clk_3>, <&misc_clk_3>, <&misc_clk_3>;
		xlnx,axis-fifo-dcnt-width = <12>;
		xlnx,mipi-slv-int = <0>;
		xlnx,csi-vc-off-7 = <8>;
		xlnx,csi-vc-off-8 = <9>;
		xlnx,csi-vc-off-9 = <10>;
		xlnx,axis-tdest-width = <11>;
		xlnx,phy-mode = "DPHY";
		xlnx,edk-iptype = "PERIPHERAL";
		xlnx,cmn-pxl-format = "RAW12";
		xlnx,csi-opt2-crc = <0>;
		clock-names = "core_clk" , "dl0_rxbyteclkhs" , "m_axis_aclk" , "s_axi_aclk" , "video_aclk";
		xlnx,yuv420-buf-dpth = <128>;
		xlnx,hp-io-bank-selection = <46>;
		xlnx,csi-opt3-fixedlanes = <0>;
		xlnx,csi-en-vc-support = <1>;
		xlnx,hs-line-rate = <1500>;
		xlnx,csi-fixed-vc = <0>;
		xlnx,csi-inv-shutdown = <1>;
		xlnx,sprt-isp-bridge;
		xlnx,axis-tdata-width = <48>;
		xlnx,header-data-width = <32>;
	};
	vcap_hier_mipi_1_mipi_csi2_rx_subsyst_0_phy: vcap_hier_mipi_1_mipi_csi2_rx_subsyst_0_phy@1000 {
		xlnx,esc-clk-period = <50>;
		compatible = "xlnx,mipi-rx-phy-1.0";
		xlnx,calib-en = <0>;
		xlnx,prbs-seed = <0000000000000001>;
		xlnx,en-timeout-regs = <0>;
		xlnx,en-alp = <0>;
		xlnx,clock-mask = <39>;
		xlnx,en-preamble-seq = <0>;
		xlnx,back2back-sync = <0>;
		xlnx,resp-width = <2>;
		xlnx,hs-timeout = <65541>;
		xlnx,ip-name = "mipi_rx_phy";
		xlnx,is-hierarchy;
		reg = <0x0 0xb0061000 0x0 0x1000>;
		xlnx,addr-width = <8>;
		xlnx,alp-pause-wake-stop = <4>;
		clocks = <&misc_clk_4>, <&misc_clk_2>, <&misc_clk_3>;
		xlnx,ppi-v-width = <1>;
		xlnx,line-rate = <1500>;
		xlnx,stable-clk-period = <200>;
		xlnx,phy-mode = <1>;
		xlnx,edk-iptype = "PERIPHERAL";
		xlnx,ppi-rxdwidth = <16>;
		xlnx,max-symbols = <16>;
		xlnx,dbg-ports-on = <0>;
		xlnx,wakeup = <200000>;
		xlnx,en-esc-mode = <0>;
		xlnx,stb-width = <4>;
		xlnx,init-cntr-1 = <1024>;
		xlnx,en-init-periodic-seq = <0>;
		xlnx,alp-pause-wake-ulps = <50>;
		clock-names = "cnts_rxwordclkhs_in" , "core_clk" , "s_axi_aclk";
		xlnx,data-width = <32>;
		xlnx,init-cntr-2 = <20>;
		xlnx,esc-timeout = <25600>;
		xlnx,en-alt-seq = <0>;
		xlnx,reg-on = <1>;
		xlnx,lib-fifo = <1>;
		xlnx,en-ulps-wakeup-cnt = <0>;
		xlnx,phy-preset = "CSI2RX_XLNX";
		xlnx,phy-lanes = <4>;
		xlnx,hs-settle = <25>;
		xlnx,ddr-clk-period = <0x145708>;
		xlnx,name = "vcap_hier_mipi_1_mipi_csi2_rx_subsyst_0_phy";
		xlnx,cts-en-phy-init = <0>;
	};
	vcap_hier_mipi_1_mipi_csi2_rx_subsyst_0_rx: vcap_hier_mipi_1_mipi_csi2_rx_subsyst_0_rx@0 {
		xlnx,ip-name = "mipi_csi2_rx_ctrl";
		reg = <0x0 0xb0060000 0x0 0x1000>;
		xlnx,ppi-sig-width = <1>;
		xlnx,cmn-inc-vfb;
		xlnx,axis-tuser-width = <112>;
		compatible = "xlnx,mipi-csi2-rx-ctrl-1.0";
		xlnx,cmn-num-pixels = <4>;
		xlnx,cmn-proj-family = <0>;
		xlnx,csi2rx-dbg = <0>;
		xlnx,csi-opt1-regs = <0>;
		xlnx,disable-lite = <0>;
		xlnx,ppi-sync-width = <0>;
		xlnx,csi-filter-userdatatype = <1>;
		xlnx,csi-offload-nonimage = <0>;
		xlnx,csi-vc-off-10 = <11>;
		xlnx,emb-dw = <96>;
		xlnx,csi-vc-off-11 = <12>;
		xlnx,csi-vc-off-12 = <13>;
		xlnx,csi-vc-off-13 = <14>;
		xlnx,csi-vc-off-14 = <15>;
		xlnx,ppi-mult = <1>;
		xlnx,name = "vcap_hier_mipi_1_mipi_csi2_rx_subsyst_0_rx";
		xlnx,en-vcx;
		xlnx,csi-vc-off-0 = <1>;
		xlnx,csi-vc-off-1 = <2>;
		xlnx,csi-vc-off-2 = <3>;
		xlnx,csi-vc-off-3 = <4>;
		xlnx,csi-vc-off-4 = <5>;
		xlnx,csi-lanes = <4>;
		xlnx,csi-vc-off-5 = <6>;
		xlnx,is-hierarchy;
		xlnx,axis-fifo-depth = <4096>;
		xlnx,csi-vc-off-6 = <7>;
		clocks = <&misc_clk_2>, <&misc_clk_6>, <&misc_clk_3>, <&misc_clk_3>, <&misc_clk_3>;
		xlnx,axis-fifo-dcnt-width = <12>;
		xlnx,mipi-slv-int = <0>;
		xlnx,csi-vc-off-7 = <8>;
		xlnx,csi-vc-off-8 = <9>;
		xlnx,csi-vc-off-9 = <10>;
		xlnx,axis-tdest-width = <11>;
		xlnx,phy-mode = "DPHY";
		xlnx,edk-iptype = "PERIPHERAL";
		xlnx,cmn-pxl-format = "RAW12";
		xlnx,csi-opt2-crc = <0>;
		clock-names = "core_clk" , "dl0_rxbyteclkhs" , "m_axis_aclk" , "s_axi_aclk" , "video_aclk";
		xlnx,yuv420-buf-dpth = <128>;
		xlnx,hp-io-bank-selection = <46>;
		xlnx,csi-opt3-fixedlanes = <0>;
		xlnx,csi-en-vc-support = <1>;
		xlnx,hs-line-rate = <1500>;
		xlnx,csi-fixed-vc = <0>;
		xlnx,csi-inv-shutdown = <1>;
		xlnx,sprt-isp-bridge;
		xlnx,axis-tdata-width = <48>;
		xlnx,header-data-width = <32>;
	};
	vcap_hier_mipi_2_mipi_csi2_rx_subsyst_0_phy: vcap_hier_mipi_2_mipi_csi2_rx_subsyst_0_phy@1000 {
		xlnx,en-csi-cnts-word-clk;
		xlnx,en-alp = <0>;
		xlnx,ip-name = "mipi_rx_phy";
		reg = <0x0 0xb0001000 0x0 0x1000>;
		xlnx,line-rate = <1500>;
		xlnx,max-symbols = <16>;
		xlnx,ppi-rxdwidth = <16>;
		xlnx,supportlevel;
		xlnx,alp-pause-wake-ulps = <93750>;
		xlnx,esc-timeout = <25600>;
		xlnx,data-width = <32>;
		xlnx,lib-fifo = <1>;
		xlnx,ddr-clk-period = <0x145708>;
		xlnx,phy-lanes = <3>;
		compatible = "xlnx,mipi-rx-phy-1.0";
		xlnx,prbs-seed = <0000000000000001>;
		xlnx,en-preamble-seq = <0>;
		xlnx,hs-timeout = <65541>;
		xlnx,alp-pause-wake-stop = <9>;
		xlnx,ppi-v-width = <0>;
		xlnx,en-esc-mode = <0>;
		xlnx,wakeup = <200000>;
		xlnx,en-init-periodic-seq = <0>;
		xlnx,stb-width = <4>;
		xlnx,en-ulps-wakeup-cnt = <0>;
		xlnx,name = "vcap_hier_mipi_2_mipi_csi2_rx_subsyst_0_phy";
		xlnx,phy-preset = "None";
		xlnx,clock-mask = <39>;
		xlnx,addr-width = <8>;
		xlnx,is-hierarchy;
		clocks = <&misc_clk_2>, <&misc_clk_3>;
		xlnx,stable-clk-period = <200>;
		xlnx,phy-mode = <0>;
		xlnx,edk-iptype = "PERIPHERAL";
		xlnx,init-cntr-1 = <1024>;
		xlnx,en-alt-seq = <0>;
		xlnx,init-cntr-2 = <17>;
		clock-names = "core_clk" , "s_axi_aclk";
		xlnx,hs-settle = <16>;
		xlnx,esc-clk-period = <50>;
		xlnx,calib-en = <0>;
		xlnx,en-timeout-regs = <0>;
		xlnx,back2back-sync = <0>;
		xlnx,resp-width = <2>;
		xlnx,dbg-ports-on = <0>;
		xlnx,reg-on = <1>;
		xlnx,cts-en-phy-init = <0>;
	};
	vcap_hier_mipi_2_mipi_csi2_rx_subsyst_0_rx: vcap_hier_mipi_2_mipi_csi2_rx_subsyst_0_rx@0 {
		xlnx,ip-name = "mipi_csi2_rx_ctrl";
		reg = <0x0 0xb0000000 0x0 0x1000>;
		xlnx,ppi-sig-width = <0>;
		xlnx,cmn-inc-vfb;
		xlnx,axis-tuser-width = <128>;
		compatible = "xlnx,mipi-csi2-rx-ctrl-1.0";
		xlnx,cmn-num-pixels = <4>;
		xlnx,cmn-proj-family = <0>;
		xlnx,csi2rx-dbg = <0>;
		xlnx,csi-opt1-regs = <0>;
		xlnx,disable-lite = <0>;
		xlnx,ppi-sync-width = <0>;
		xlnx,csi-filter-userdatatype = <1>;
		xlnx,csi-offload-nonimage = <0>;
		xlnx,csi-vc-off-10 = <11>;
		xlnx,emb-dw = <96>;
		xlnx,csi-vc-off-11 = <12>;
		xlnx,csi-vc-off-12 = <13>;
		xlnx,csi-vc-off-13 = <14>;
		xlnx,csi-vc-off-14 = <15>;
		xlnx,ppi-mult = <1>;
		xlnx,name = "vcap_hier_mipi_2_mipi_csi2_rx_subsyst_0_rx";
		xlnx,en-vcx;
		xlnx,csi-vc-off-0 = <1>;
		xlnx,csi-vc-off-1 = <2>;
		xlnx,csi-vc-off-2 = <3>;
		xlnx,csi-vc-off-3 = <4>;
		xlnx,csi-vc-off-4 = <5>;
		xlnx,csi-lanes = <3>;
		xlnx,csi-vc-off-5 = <6>;
		xlnx,is-hierarchy;
		xlnx,axis-fifo-depth = <4096>;
		xlnx,csi-vc-off-6 = <7>;
		clocks = <&misc_clk_2>, <&misc_clk_4>, <&misc_clk_3>, <&misc_clk_3>, <&misc_clk_3>;
		xlnx,axis-fifo-dcnt-width = <12>;
		xlnx,mipi-slv-int = <0>;
		xlnx,csi-vc-off-7 = <8>;
		xlnx,csi-vc-off-8 = <9>;
		xlnx,csi-vc-off-9 = <10>;
		xlnx,axis-tdest-width = <11>;
		xlnx,phy-mode = "CPHY";
		xlnx,edk-iptype = "PERIPHERAL";
		xlnx,cmn-pxl-format = "RAW12";
		xlnx,csi-opt2-crc = <0>;
		clock-names = "core_clk" , "dl0_rxbyteclkhs" , "m_axis_aclk" , "s_axi_aclk" , "video_aclk";
		xlnx,yuv420-buf-dpth = <128>;
		xlnx,hp-io-bank-selection = <46>;
		xlnx,csi-opt3-fixedlanes = <1>;
		xlnx,csi-en-vc-support = <1>;
		xlnx,hs-line-rate = <1500>;
		xlnx,csi-fixed-vc = <0>;
		xlnx,csi-inv-shutdown = <1>;
		xlnx,sprt-isp-bridge;
		xlnx,axis-tdata-width = <48>;
		xlnx,header-data-width = <48>;
	};
	vcap_visp_ss_0_visp_ip: vcap_visp_ss_0_visp_ip@0 {
		xlnx,hdl-tile2-dpll-divclk-divide = <1>;
		xlnx,hdl-tile2-dpll-clkfbout-fract = <0>;
		xlnx,tile1-config = <0>;
		xlnx,tile1-isp1-iba3-data-format = <16>;
		xlnx,tile0-isp0-mem-inputs = <0>;
		xlnx,tile0-isp1-iba4-fps = <60>;
		xlnx,tile2-isp0-mem-inputs = <0>;
		xlnx,tile1-isp1-io-type = <2>;
		xlnx,hdl-tile2-vidin3-tdata-width = <48>;
		xlnx,hdl-tile0-vidin0-tuser-width = <96>;
		xlnx,debug-tile2-iba3-bypass = <0>;
		xlnx,debug-tile0-clk-src-dpll;
		xlnx,tile1-isp0-iba3-vcid = <3>;
		xlnx,tile1-isp0-oba0-mp-y;
		xlnx,tile2-isp0-iba1-res-hor = <3840>;
		xlnx,tile0-common-iba3-ppc = <4>;
		reg = <0x0 0x000 0x0 0x1000 0x0 0xe8500000 0x0 0x100000 0x0 0xe8600000 0x0 0x100000 0x0 0xe8700000 0x0 0x100000>;
		xlnx,tile0-isp0-iba3-data-format = <12>;
		xlnx,tile1-isp0-iba1-fps = <15>;
		xlnx,tile2-vidout01-tdata-width = <120>;
		xlnx,tile2-isp0-iba2-data-format = <12>;
		xlnx,hdl-tile0-dpll-clkin-period = <0x65b9d7>;
		xlnx,tile2-common-iba3-ppc = <4>;
		xlnx,tile0-enable;
		xlnx,tile1-isp0-iba0-res-ver = <2160>;
		xlnx,tile1-isp1-oba1-mp-bpp = <10>;
		xlnx,hdl-tile1-vidin0-tdata-width = <48>;
		xlnx,tile0-dpll-divclk-divide = <1>;
		xlnx,tile0-isp0-core-clk = <0x2aea05e0>;
		xlnx,tile1-isp0-iba0-vcid = <0>;
		xlnx,hdl-tile1-vidout02-bpp = <10>;
		xlnx,hdl-tile0-vidin4-ppc = <4>;
		xlnx,debug-tile1-apb-clk-src-axi;
		xlnx,tile2-isp0-netfps = <60>;
		xlnx,tile2-isp1-oba1-sp-y;
		xlnx,tile0-isp1-oba1-ppc = <4>;
		xlnx,tile0-vidin3-tdata-width = <48>;
		xlnx,hdl-tile2-isp1-iba4-res-hor = <3840>;
		xlnx,tile0-isp1-iba4-res-hor = <3840>;
		xlnx,tile1-common-iba3-res-ver = <2160>;
		xlnx,hdl-tile1-vidout11-bpp = <10>;
		xlnx,debug-tile2-iba1-bypass = <0>;
		xlnx,hdl-tile1-vidout12-ppc = <4>;
		xlnx,tile2-isp0-iba2-vcid = <2>;
		xlnx,tile2-isp0-oba0-sp-rgb888;
		xlnx,tile0-isp0-iba3-fps = <15>;
		xlnx,hdl-tile1-vidin3-data-format = <12>;
		xlnx,tile1-vidin0-tuser-width = <96>;
		xlnx,tile2-isp0-iba1-res-ver = <2160>;
		xlnx,tile0-isp1-io-type = <2>;
		xlnx,tile0-isp1-mem-inputs = <0>;
		xlnx,tile1-isp0-actual-core-clk = <720>;
		xlnx,hdl-llpath0-tile = <3>;
		xlnx,tile0-common-iba3-data-format = <12>;
		xlnx,tile0-isp0-oba0-sp-bpp = <10>;
		xlnx,tile0-isp1-iba4-ppc = <4>;
		xlnx,tile1-isp0-oba0-sp-y;
		xlnx,debug-clock-gate = <0>;
		xlnx,tile2-isp1-mem-inputs = <0>;
		xlnx,hdl-tile2-isp1-iba4-vcid = <0>;
		xlnx,hdl-tile0-vidin0-data-format = <12>;
		xlnx,tile2-vidin0-tdata-width = <48>;
		xlnx,tile2-common-iba3-res-hor = <3840>;
		xlnx,tile0-isp1-oba1-sp-rgb888;
		xlnx,tile2-ref-clk = <0x8f0cd98>;
		xlnx,name = "vcap_visp_ss_0_visp_ip";
		xlnx,tile1-isp1-oba1-sp-yuv422;
		xlnx,tile1-isp0-iba1-ppc = <4>;
		xlnx,hdl-tile2-isp0-iba0-res-hor = <3840>;
		xlnx,hdl-tile0-vidout02-bpp = <10>;
		xlnx,tile0-isp0-iba0-res-hor = <3840>;
		xlnx,hdl-tile2-vidin2-tdata-width = <48>;
		xlnx,debug-tile1-iba3-bypass = <0>;
		xlnx,tile0-isp0-oba0-ppc = <4>;
		xlnx,tile0-isp1-iba4-res-ver = <2160>;
		xlnx,hdl-tile1-vidin4-ppc = <4>;
		xlnx,tile0-isp0-iba2-data-format = <12>;
		xlnx,tile0-isp0-oba0-mp-bpp = <10>;
		xlnx,is-hierarchy;
		xlnx,tile2-isp0-iba1-data-format = <12>;
		xlnx,hdl-tile1-dpll-clkfbout-mult = <24>;
		xlnx,hdl-tile0-vidin1-ppc = <4>;
		xlnx,tile0-dpll-clkout3-divide = <5>;
		xlnx,hdl-tile0-vidout11-bpp = <10>;
		xlnx,hdl-tile2-isp-core-1-resolution-mp = <8>;
		xlnx,tile1-isp0-netfps = <60>;
		xlnx,hdl-tile0-vidout12-ppc = <4>;
		clock-names = "s_axi_lite_aclk" , "tile0_pl_isp_vidin0_clk" , "tile0_pl_isp_vidin1_clk" , "tile0_pl_isp_vidin2_clk" , "tile0_pl_isp_vidin3_clk" , "tile0_pl_isp_vidin4_clk" , "tile0_ref_dpll_clk" , "tile1_pl_isp_vidin0_clk" , "tile1_pl_isp_vidin1_clk" , "tile1_pl_isp_vidin2_clk" , "tile1_pl_isp_vidin3_clk" , "tile1_pl_isp_vidin4_clk" , "tile1_ref_dpll_clk" , "tile2_pl_isp_vidin0_clk" , "tile2_pl_isp_vidin1_clk" , "tile2_pl_isp_vidin2_clk" , "tile2_pl_isp_vidin3_clk" , "tile2_pl_isp_vidin4_clk" , "tile2_ref_dpll_clk";
		xlnx,tile2-isp0-oba0-sp-bpp = <10>;
		xlnx,tile0-vidin2-tdata-width = <48>;
		xlnx,hdl-tile1-isp0-iba0-vcid = <0>;
		xlnx,tile0-isp0-oba0-mp-yuv422;
		xlnx,hdl-tile1-isp-core-0-resolution-mp = <8>;
		xlnx,tile2-common-iba3-res-ver = <2160>;
		xlnx,tile0-isp0-iba3-ppc = <4>;
		xlnx,debug-tile1-iba1-bypass = <0>;
		xlnx,tile1-isp1-iba4-fps = <60>;
		xlnx,hdl-tile0-vidin4-tdata-width = <64>;
		xlnx,tile0-isp0-iba0-fps = <15>;
		xlnx,tile1-isp0-iba1-res-hor = <3840>;
		xlnx,llpath0-tile = <3>;
		xlnx,tile2-isp0-oba0-mp-bpp = <10>;
		xlnx,tile2-isp0-iba1-fps = <15>;
		xlnx,tile0-isp0-iba0-res-ver = <2160>;
		xlnx,hdl-tile1-vidin2-data-format = <12>;
		xlnx,ppc-converter-s2-isp = <0>;
		xlnx,hdl-tile2-vidin4-tuser-width = <96>;
		xlnx,tile1-isp0-core-clk = <0x2aea05e0>;
		xlnx,hdl-tile0-dpll-clkout-divide2 = <5>;
		xlnx,tile2-dpll-clkfbout-mult = <24>;
		xlnx,hdl-tile2-vidin4-ppc = <4>;
		xlnx,hdl-tile1-isp1-iba4-res-hor = <3840>;
		xlnx,hdl-tile0-dpll-clkout-divide3 = <5>;
		xlnx,tile1-isp1-oba1-sp-rgb888;
		xlnx,tile1-isp1-oba1-ppc = <4>;
		xlnx,tile1-isp1-oba1-mp-y;
		xlnx,tile1-isp1-iba4-vcid = <0>;
		xlnx,tile2-isp1-oba1-sp-yuv422;
		xlnx,hdl-tile1-vidin1-ppc = <4>;
		xlnx,llpath0-clk = <150>;
		xlnx,hdl-tile2-vidin1-tdata-width = <48>;
		xlnx,debug-tile0-iba3-bypass = <0>;
		xlnx,tile2-isp0-rpu = <8>;
		xlnx,tile2-isp0-actual-core-clk = <720>;
		xlnx,tile0-isp0-iba1-data-format = <12>;
		xlnx,tile0-vidin4-tuser-width = <96>;
		xlnx,tile2-isp0-iba0-data-format = <12>;
		xlnx,hdl-tile1-isp-core-0-frame-rate = <60>;
		xlnx,tile2-isp0-iba2-res-hor = <3840>;
		xlnx,hdl-llpath1-oba = <0>;
		xlnx,tile1-vidin4-tdata-width = <48>;
		xlnx,tile1-isp0-iba3-fps = <15>;
		xlnx,tile1-isp0-iba1-res-ver = <2160>;
		xlnx,tile0-isp0-netfps = <60>;
		xlnx,tile1-dpll-clkout3-divide = <5>;
		xlnx,llpath1-oba = <0>;
		xlnx,tile0-isp0-iba3-vcid = <3>;
		xlnx,tile0-isp0-oba0-mp-y;
		xlnx,tile0-vidin1-tdata-width = <48>;
		xlnx,tile1-isp1-iba4-ppc = <4>;
		xlnx,tile1-isp1-live-inputs = <1>;
		xlnx,tile2-dpll-clkin-period = <0x65b9d7>;
		xlnx,hdl-tile0-dpll-divclk-divide = <1>;
		xlnx,tile0-isp0-iba0-ppc = <4>;
		xlnx,tile0-isp0-oba0-mp-rgb888;
		xlnx,tile2-isp1-iba3-vcid = <0>;
		xlnx,tile1-isp0-oba0-mp-yuv422;
		xlnx,hdl-tile1-isp0-iba0-res-hor = <3840>;
		xlnx,debug-tile0-iba1-bypass = <0>;
		xlnx,tile2-isp0-iba1-ppc = <4>;
		xlnx,tile0-isp0-iba0-vcid = <0>;
		xlnx,tile0-dpll-clkfbout-fract = <0>;
		xlnx,tile2-isp1-iba4-data-format = <16>;
		xlnx,tile0-isp1-rpu = <6>;
		xlnx,tile1-common-iba3-vcid = <3>;
		xlnx,hdl-tile2-vidout01-bpp = <10>;
		xlnx,hdl-tile2-vidin4-data-format = <16>;
		xlnx,hdl-tile0-vidin3-tdata-width = <48>;
		xlnx,tile0-isp1-core-clk = <0x2aea05e0>;
		xlnx,hdl-tile0-vidout12-tdata-width = <120>;
		xlnx,tile0-isp0-oba0-sp-ir;
		xlnx,hdl-tile2-vidout02-ppc = <4>;
		xlnx,hdl-tile2-isp-core-0-no-of-sensors = <4>;
		xlnx,tile1-isp1-oba1-sp-y;
		xlnx,tile1-isp0-oba0-ppc = <4>;
		xlnx,tile2-isp0-oba0-sp-ir;
		xlnx,hdl-tile1-vidin1-data-format = <12>;
		xlnx,hdl-tile2-vidin1-ppc = <4>;
		xlnx,tile2-isp0-iba2-res-ver = <2160>;
		xlnx,tile1-isp0-iba2-vcid = <2>;
		xlnx,hdl-tile2-vidout11-ppc = <4>;
		xlnx,hdl-tile1-vidin0-tuser-width = <96>;
		xlnx,hdl-tile1-dpll-clkout-divide2 = <5>;
		xlnx,tile0-isp1-oba1-sp-ir;
		xlnx,hdl-tile1-dpll-clkout-divide3 = <5>;
		xlnx,hdl-tile1-isp-core-1-frame-rate = <60>;
		xlnx,tile2-isp1-oba1-sp-rgb888;
		xlnx,tile2-isp1-oba1-sp-ir;
		xlnx,tile0-isp1-iba3-fps = <0>;
		xlnx,hdl-llpath0-tdest-val = <0>;
		xlnx,hdl-tile2-vidin0-tdata-width = <48>;
		xlnx,hdl-tile1-isp-core-1-resolution-mp = <8>;
		xlnx,hdl-llpath1-iba = <0>;
		xlnx,tile0-isp0-oba0-sp-y;
		xlnx,tile1-dpll-divclk-divide = <1>;
		xlnx,tile1-isp0-iba3-ppc = <4>;
		xlnx,tile2-isp1-iba4-fps = <60>;
		xlnx,tile0-isp0-iba0-data-format = <12>;
		xlnx,hdl-tile1-isp1-iba4-vcid = <0>;
		xlnx,tile0-isp0-iba1-res-hor = <3840>;
		xlnx,llpath1-iba = <0>;
		xlnx,tile1-isp0-iba0-fps = <15>;
		xlnx,hdl-tile1-enable;
		xlnx,tile1-vidin3-tdata-width = <48>;
		xlnx,hdl-tile0-isp-core-0-resolution-mp = <8>;
		xlnx,debug-tile2-expose-allintf-allports = <0>;
		xlnx,hdl-tile1-vidout01-bpp = <10>;
		xlnx,edk-iptype = "PERIPHERAL";
		xlnx,hdl-tile0-vidout02-tdata-width = <120>;
		xlnx,hdl-tile0-vidin3-ppc = <4>;
		xlnx,tile2-dpll-clkout3-divide = <5>;
		xlnx,tile0-vidin0-tdata-width = <48>;
		xlnx,tile1-isp0-live-inputs = <4>;
		xlnx,hdl-tile1-vidout02-ppc = <4>;
		xlnx,tile2-isp0-iba1-vcid = <1>;
		xlnx,tile2-isp0-core-clk = <0x2aea05e0>;
		xlnx,hdl-tile0-isp1-iba4-res-hor = <3840>;
		xlnx,tile1-common-iba3-fps = <15>;
		xlnx,tile1-isp0-oba0-mp-rgb888;
		xlnx,tile2-isp1-oba1-ppc = <4>;
		xlnx,tile0-isp1-iba4-data-format = <16>;
		xlnx,tile2-isp1-iba3-res-hor = <3840>;
		xlnx,tile2-isp1-iba3-data-format = <16>;
		xlnx,tile2-isp0-oba0-mp-yuv422;
		xlnx,hdl-tile2-vidin3-data-format = <12>;
		xlnx,hdl-tile0-vidin2-tdata-width = <48>;
		xlnx,tile2-vidin0-tuser-width = <96>;
		xlnx,tile0-isp1-actual-core-clk = <720>;
		xlnx,tile1-dpll-clkfbout-fract = <0>;
		xlnx,hdl-tile0-vidout11-tdata-width = <120>;
		xlnx,hdl-tile1-vidout11-ppc = <4>;
		xlnx,tile0-isp1-oba1-sp-bpp = <10>;
		xlnx,hdl-tile1-vidin0-data-format = <12>;
		xlnx,hdl-tile0-isp0-iba0-vcid = <0>;
		xlnx,tile0-isp0-iba2-fps = <15>;
		xlnx,tile1-isp0-iba2-res-hor = <3840>;
		xlnx,tile1-isp0-iba3-data-format = <12>;
		xlnx,tile0-isp0-iba1-res-ver = <2160>;
		xlnx,hdl-tile0-enabledpll;
		xlnx,tile2-isp0-iba3-fps = <15>;
		xlnx,tile2-config = <0>;
		xlnx,tile0-isp1-oba1-mp-yuv422;
		xlnx,tile0-isp1-iba3-ppc = <4>;
		xlnx,tile1-dpll-clkin-period = <0x65b9d7>;
		xlnx,hdl-tile1-vidout12-tdata-width = <120>;
		xlnx,tile2-isp1-iba4-ppc = <4>;
		xlnx,debug-tile2-iba4-bypass = <0>;
		xlnx,hdl-tile2-dpll-clkout-divide2 = <5>;
		xlnx,tile0-isp1-oba1-mp-bpp = <10>;
		xlnx,tile0-vidout12-tdata-width = <120>;
		xlnx,tile1-isp0-iba0-ppc = <4>;
		xlnx,hdl-tile2-dpll-clkout-divide3 = <5>;
		xlnx,hdl-tile0-isp0-iba0-res-hor = <3840>;
		xlnx,hdl-tile0-vidout01-bpp = <10>;
		xlnx,tile1-enable;
		xlnx,hdl-tile2-dpll-clkfbout-mult = <24>;
		xlnx,tile1-isp0-mem-inputs = <0>;
		xlnx,hdl-tile0-vidout02-ppc = <4>;
		xlnx,hdl-tile1-vidin3-ppc = <4>;
		xlnx,tile1-isp1-core-clk = <0x2aea05e0>;
		xlnx,tile2-isp1-netfps = <60>;
		xlnx,tile2-isp1-iba3-res-ver = <2160>;
		xlnx,hdl-tile2-isp-core-1-no-of-sensors = <1>;
		xlnx,tile2-isp0-oba0-ppc = <4>;
		xlnx,tile1-vidin2-tdata-width = <48>;
		xlnx,tile0-isp1-iba4-vcid = <0>;
		xlnx,tile0-isp1-oba1-mp-y;
		xlnx,tile2-isp1-oba1-sp-bpp = <10>;
		xlnx,tile0-config = <0>;
		xlnx,tile1-common-iba3-ppc = <4>;
		xlnx,hdl-tile0-vidin0-ppc = <4>;
		xlnx,tile2-isp0-iba3-res-hor = <3840>;
		xlnx,hdl-tile0-vidin4-tuser-width = <96>;
		xlnx,hdl-tile0-vidout01-tdata-width = <120>;
		xlnx,debug-tile0-expose-scandfx-ports = <0>;
		xlnx,tile1-isp0-iba2-res-ver = <2160>;
		xlnx,hdl-tile0-vidout11-ppc = <4>;
		xlnx,debug-tile0-apb-clk-src-axi;
		xlnx,tile0-dpll-clkfbout-mult = <24>;
		xlnx,hdl-tile1-isp-core-0-no-of-sensors = <4>;
		xlnx,debug-tile2-iba2-bypass = <0>;
		xlnx,hdl-tile1-vidin4-tdata-width = <48>;
		xlnx,debug-tile2-apb-clk-src-axi;
		xlnx,tile0-isp1-iba3-data-format = <16>;
		xlnx,tile2-isp0-oba0-mp-rgb888;
		compatible = "xlnx,visp-2.0";
		xlnx,tile0-isp0-iba2-ppc = <4>;
		xlnx,hdl-tile2-vidin2-data-format = <12>;
		xlnx,hdl-tile0-vidin1-tdata-width = <48>;
		xlnx,tile2-isp1-oba1-mp-bpp = <10>;
		xlnx,tile1-isp1-iba3-fps = <0>;
		xlnx,hdl-tile1-enabledpll;
		xlnx,tile2-isp0-iba3-ppc = <4>;
		xlnx,tile2-dpll-clkfbout-fract = <0>;
		xlnx,hdl-tile1-vidout02-tdata-width = <120>;
		xlnx,tile2-isp0-iba0-fps = <15>;
		xlnx,tile0-vidout02-tdata-width = <120>;
		xlnx,tile1-isp0-iba2-data-format = <12>;
		xlnx,tile1-isp1-iba3-vcid = <0>;
		xlnx,ppc-converter-s1-isp = <0>;
		xlnx,tile0-isp1-oba1-mp-rgb888;
		xlnx,hdl-tile0-isp-core-1-resolution-mp = <8>;
		xlnx,debug-tile2-iba0-bypass = <0>;
		xlnx,tile1-isp1-oba1-mp-yuv422;
		xlnx,tile1-isp1-rpu = <7>;
		xlnx,tile1-isp1-actual-core-clk = <720>;
		xlnx,tile1-isp1-mem-inputs = <0>;
		xlnx,hdl-tile1-vidout11-tdata-width = <120>;
		xlnx,tile2-isp0-iba3-res-ver = <2160>;
		xlnx,tile0-isp1-oba1-sp-y;
		xlnx,hdl-tile2-vidout12-bpp = <10>;
		xlnx,hdl-tile2-vidin3-ppc = <4>;
		xlnx,debug-tile1-iba4-bypass = <0>;
		xlnx,tile2-common-iba3-data-format = <12>;
		xlnx,tile1-vidin4-tuser-width = <96>;
		xlnx,tile0-ref-clk = <0x8f0cd98>;
		xlnx,tile0-vidout11-tdata-width = <120>;
		xlnx,tile1-isp1-iba3-res-hor = <3840>;
		xlnx,hdl-tile1-vidin0-ppc = <4>;
		xlnx,hdl-tile0-vidin4-data-format = <16>;
		xlnx,tile2-vidin4-tdata-width = <64>;
		xlnx,tile0-isp0-iba2-vcid = <2>;
		xlnx,tile1-isp0-oba0-sp-bpp = <10>;
		xlnx,tile1-isp1-netfps = <60>;
		xlnx,tile1-vidin1-tdata-width = <48>;
		xlnx,tile0-isp0-iba2-res-hor = <3840>;
		xlnx,hdl-tile2-vidout12-tdata-width = <120>;
		xlnx,hdl-tile1-dpll-divclk-divide = <1>;
		xlnx,hdl-llpath0-oba = <0>;
		xlnx,debug-tile1-expose-allintf-allports = <0>;
		xlnx,tile1-isp0-iba2-fps = <15>;
		xlnx,tile1-vidout12-tdata-width = <120>;
		xlnx,hdl-tile2-dpll-clkin-period = <0x65b9d7>;
		xlnx,speedgrade = "-2mp";
		xlnx,llpath0-oba = <0>;
		xlnx,hdl-tile2-enabledpll;
		xlnx,hdl-tile0-isp1-iba4-vcid = <0>;
		xlnx,debug-tile1-iba2-bypass = <0>;
		xlnx,tile2-isp0-io-type = <2>;
		xlnx,tile0-dpll-clkin-period = <0x65b9d7>;
		xlnx,tile1-isp1-iba3-ppc = <4>;
		xlnx,hdl-tile1-vidin3-tdata-width = <48>;
		xlnx,tile1-isp0-oba0-mp-bpp = <10>;
		xlnx,hdl-tile2-vidin1-data-format = <12>;
		xlnx,hdl-tile0-vidin0-tdata-width = <48>;
		xlnx,tile2-isp0-iba0-ppc = <4>;
		xlnx,tile0-dpll-clkout2-divide = <5>;
		xlnx,tile0-isp0-rpu = <6>;
		xlnx,tile2-isp1-iba4-res-hor = <3840>;
		xlnx,hdl-tile1-vidout01-tdata-width = <120>;
		xlnx,debug-tile1-expose-scandfx-ports = <0>;
		xlnx,tile1-isp0-iba1-vcid = <1>;
		xlnx,hdl-tile2-vidout01-ppc = <4>;
		xlnx,hdl-tile1-vidout12-bpp = <10>;
		xlnx,tile1-isp1-iba3-res-ver = <2160>;
		xlnx,tile2-isp1-core-clk = <0x2aea05e0>;
		xlnx,tile0-isp0-oba0-sp-yuv422;
		xlnx,tile0-vidout01-tdata-width = <120>;
		xlnx,tile1-isp0-iba1-data-format = <12>;
		xlnx,hdl-tile2-vidin0-tuser-width = <96>;
		xlnx,ppc-converter-num-streams = <0>;
		xlnx,tile1-isp0-iba3-res-hor = <3840>;
		xlnx,hdl-tile2-isp-core-0-frame-rate = <60>;
		xlnx,llpath1-delay = <278>;
		xlnx,debug-tile1-iba0-bypass = <0>;
		xlnx,tile0-isp0-iba2-res-ver = <2160>;
		xlnx,tile1-isp1-oba1-mp-rgb888;
		xlnx,hdl-tile2-vidin0-ppc = <4>;
		xlnx,tile2-isp1-oba1-mp-yuv422;
		xlnx,tile2-dpll-divclk-divide = <1>;
		xlnx,debug-tile0-iba4-bypass = <0>;
		xlnx,hdl-tile2-vidout02-tdata-width = <120>;
		xlnx,hdl-tile1-isp-core-1-no-of-sensors = <1>;
		xlnx,hdl-tile0-dpll-clkfbout-fract = <0>;
		xlnx,tile2-isp0-oba0-mp-y;
		xlnx,tile2-isp0-iba3-vcid = <3>;
		xlnx,tile1-vidout02-tdata-width = <120>;
		xlnx,hdl-tile0-vidin3-data-format = <12>;
		xlnx,tile2-vidin3-tdata-width = <48>;
		xlnx,tile0-vidin0-tuser-width = <96>;
		xlnx,hdl-llpath0-iba = <0>;
		xlnx,tile1-isp0-iba2-ppc = <4>;
		xlnx,tile2-isp1-iba3-fps = <0>;
		xlnx,tile1-isp0-io-type = <2>;
		xlnx,hdl-tile0-isp-core-0-no-of-sensors = <4>;
		xlnx,tile2-isp0-iba0-vcid = <0>;
		xlnx,tile0-isp1-live-inputs = <1>;
		xlnx,tile0-isp1-netfps = <60>;
		xlnx,hdl-llpath1-tile = <3>;
		xlnx,tile2-isp1-actual-core-clk = <720>;
		xlnx,tile1-vidin0-tdata-width = <48>;
		xlnx,llpath0-iba = <0>;
		xlnx,hdl-tile2-vidout11-tdata-width = <120>;
		xlnx,hdl-llpath1-delay = <41>;
		xlnx,tile2-isp0-iba0-res-hor = <3840>;
		xlnx,ip-name = "visp";
		xlnx,tile2-isp1-iba4-res-ver = <2160>;
		xlnx,tile1-vidout11-tdata-width = <120>;
		xlnx,llpath0-delay = <278>;
		xlnx,tile0-common-iba3-vcid = <3>;
		xlnx,hdl-tile0-vidin2-ppc = <4>;
		xlnx,debug-tile0-iba2-bypass = <0>;
		xlnx,hdl-tile1-vidout01-ppc = <4>;
		xlnx,hdl-tile1-vidin2-tdata-width = <48>;
		xlnx,hdl-tile0-vidout12-bpp = <10>;
		xlnx,tile1-isp0-iba3-res-ver = <2160>;
		xlnx,hdl-tile2-vidin0-data-format = <12>;
		xlnx,tile0-isp1-iba3-res-hor = <3840>;
		xlnx,hdl-tile0-dpll-clkfbout-mult = <24>;
		xlnx,hdl-tile2-isp-core-1-frame-rate = <60>;
		xlnx,tile2-vidout12-tdata-width = <120>;
		xlnx,tile1-dpll-clkout2-divide = <5>;
		xlnx,hdl-llpath0-delay = <41>;
		xlnx,tile2-isp0-oba0-sp-y;
		xlnx,tile0-isp0-oba0-sp-rgb888;
		xlnx,tile1-isp0-iba0-data-format = <12>;
		xlnx,tile2-isp1-live-inputs = <1>;
		xlnx,tile0-isp0-iba1-fps = <15>;
		xlnx,tile1-isp0-oba0-sp-ir;
		xlnx,hdl-tile0-isp-core-0-frame-rate = <60>;
		xlnx,tile1-isp0-oba0-sp-yuv422;
		xlnx,debug-tile2-clk-src-dpll;
		xlnx,debug-tile0-iba0-bypass = <0>;
		xlnx,tile2-isp0-iba2-fps = <15>;
		xlnx,hdl-tile1-dpll-clkin-period = <0x65b9d7>;
		xlnx,tile2-isp0-iba0-res-ver = <2160>;
		xlnx,tile0-isp0-io-type = <2>;
		xlnx,tile2-isp1-oba1-mp-rgb888;
		xlnx,ppc-converter-s3-isp = <0>;
		xlnx,tile2-common-iba3-vcid = <3>;
		xlnx,tile0-common-iba3-res-hor = <3840>;
		xlnx,hdl-tile2-vidout01-tdata-width = <120>;
		xlnx,debug-tile2-expose-scandfx-ports = <0>;
		xlnx,tile2-isp1-iba3-ppc = <4>;
		xlnx,tile1-common-iba3-data-format = <12>;
		xlnx,tile0-isp1-iba3-vcid = <0>;
		xlnx,tile1-vidout01-tdata-width = <120>;
		xlnx,tile1-ref-clk = <0x8f0cd98>;
		xlnx,hdl-tile2-enable;
		xlnx,hdl-tile1-dpll-clkfbout-fract = <0>;
		xlnx,hdl-tile0-vidin2-data-format = <12>;
		xlnx,tile2-vidin2-tdata-width = <48>;
		xlnx,tile1-isp1-oba1-sp-ir;
		xlnx,llpath1-tile = <3>;
		xlnx,tile1-isp1-iba4-data-format = <12>;
		xlnx,tile1-isp1-iba4-res-hor = <3840>;
		xlnx,hdl-tile1-vidin4-tuser-width = <96>;
		xlnx,hdl-tile0-vidout01-ppc = <4>;
		xlnx,tile0-isp0-live-inputs = <4>;
		xlnx,hdl-tile1-vidin2-ppc = <4>;
		xlnx,llpath1-clk = <150>;
		xlnx,tile0-isp1-iba3-res-ver = <2160>;
		xlnx,tile2-isp1-rpu = <8>;
		xlnx,tile1-dpll-clkfbout-mult = <24>;
		xlnx,hdl-tile2-vidin4-tdata-width = <64>;
		xlnx,debug-tile0-expose-allintf-allports = <0>;
		xlnx,tile0-isp0-iba3-res-hor = <3840>;
		xlnx,hdl-tile2-isp0-iba0-vcid = <0>;
		xlnx,tile2-vidout02-tdata-width = <120>;
		xlnx,tile2-isp0-iba3-data-format = <12>;
		xlnx,hdl-tile1-vidin1-tdata-width = <48>;
		xlnx,tile2-isp1-io-type = <2>;
		xlnx,tile0-common-iba3-fps = <15>;
		xlnx,hdl-tile0-enable;
		xlnx,debug-tile1-clk-src-dpll;
		xlnx,tile2-common-iba3-fps = <15>;
		xlnx,hdl-tile0-isp-core-1-frame-rate = <60>;
		xlnx,tile0-isp0-iba1-ppc = <4>;
		xlnx,tile0-common-iba3-res-ver = <2160>;
		xlnx,tile0-vidin4-tdata-width = <64>;
		xlnx,tile2-vidout11-tdata-width = <120>;
		xlnx,tile0-isp0-actual-core-clk = <720>;
		xlnx,hdl-llpath1-tdest-val = <0>;
		xlnx,tile2-isp0-iba2-ppc = <4>;
		xlnx,tile2-dpll-clkout2-divide = <5>;
		xlnx,hdl-tile2-vidout02-bpp = <10>;
		xlnx,hdl-tile0-isp-core-1-no-of-sensors = <1>;
		xlnx,tile2-isp0-live-inputs = <4>;
		xlnx,tile1-isp0-iba0-res-hor = <3840>;
		xlnx,tile1-isp0-oba0-sp-rgb888;
		xlnx,tile1-isp1-iba4-res-ver = <2160>;
		xlnx,tile2-vidin4-tuser-width = <96>;
		xlnx,tile2-isp0-oba0-sp-yuv422;
		xlnx,ppc-converter-s0-isp = <0>;
		xlnx,tile2-isp1-oba1-mp-y;
		xlnx,tile2-isp1-iba4-vcid = <0>;
		xlnx,hdl-tile2-isp-core-0-resolution-mp = <8>;
		xlnx,hdl-tile1-vidin4-data-format = <12>;
		xlnx,tile2-enable;
		xlnx,tile0-isp0-iba1-vcid = <1>;
		xlnx,tile0-isp0-iba3-res-ver = <2160>;
		xlnx,tile1-isp0-rpu = <7>;
		xlnx,hdl-tile2-vidout11-bpp = <10>;
		xlnx,hdl-tile2-vidin2-ppc = <4>;
		xlnx,tile1-common-iba3-res-hor = <3840>;
		xlnx,hdl-tile2-vidout12-ppc = <4>;
		xlnx,hdl-tile0-vidin1-data-format = <12>;
		xlnx,tile2-vidin1-tdata-width = <48>;
		xlnx,tile1-isp1-oba1-sp-bpp = <10>;
		xlnx,tile0-isp1-oba1-sp-yuv422;
	};
	aie_core_ref_clk_0: aie_core_ref_clk_0 {
		compatible = "fixed-clock";
		clock-frequency = <1250000000>;
		#clock-cells = <0>;
	};
	visp_ss_00: visp_ss@b0002000 {
		xlnx,iba1_frame_rate = <15>;
		compatible = "xlnx,visp-ss-limo-1.0";
		interrupts = <0 106 4> , <0 107 4> , <0 104 4> , <0 105 4>;
		xlnx,iba2_vcid = <2>;
		xlnx,iba3_frame_rate = <15>;
		xlnx,io_mode = "limo";
		xlnx,iba0_data_format = <12>;
		xlnx,iba1_data_format = <12>;
		xlnx,iba0_max-width = <3840>;
		interrupt-parent = <&gic>;
		xlnx,num_streams = <4>;
		xlnx,iba2_data_format = <12>;
		xlnx,iba1_max-width = <3840>;
		xlnx,ip-name = "visp_ss";
		xlnx,iba3_data_format = <12>;
		xlnx,iba2_max-width = <3840>;
		xlnx,iba1_max-height = <2160>;
		reg = <0x0 0xb0002000 0x0 0x800>;
		xlnx,netfps = <60>;
		xlnx,iba3_max-width = <3840>;
		xlnx,iba0_frame_rate = <15>;
		xlnx,iba3_max-height = <2160>;
		xlnx,iba1_vcid = <1>;
		isp_id = <0>;
		xlnx,iba2_frame_rate = <15>;
		xlnx,iba3_vcid = <3>;
		xlnx,iba0_ppc = <4>;
		xlnx,iba1_ppc = <4>;
		xlnx,iba0_max-height = <2160>;
		xlnx,rpu = <6>;
		xlnx,iba2_ppc = <4>;
		interrupt-names = "tile0_isp0_fusa_irq" , "tile0_isp0_isp_irq" , "tile0_isp_isr_irq" , "tile0_isp_xmpu_interrupt";
		xlnx,iba3_ppc = <4>;
		xlnx,iba2_max-height = <2160>;
		xlnx,iba0_vcid = <0>;
		xlnx,name = "visp_ss_00";
		xlnx,mem_inputs = <0>;
		ports00: ports {
			#address-cells = <1>;
			#size-cells = <0>;
			visp_ss_000vcap_visp_ss_0: port@0 {
				reg = <0>;
				vcap_visp_ss_0vcap_hier_mipi_0_mipi_csi2_rx_subsyst_0: endpoint {
					remote-endpoint = <&mipi_csirx_outvcap_hier_mipi_0_mipi_csi2_rx_subsyst_0>;
				};
			};
			port01: port@1 {
				reg = <1>;
				visp_isp0_port00_mp: endpoint {
					type = "output";
					remote-endpoint = <&visp_video_0_0_0>;
				};
			};
			port02: port@2 {
				reg = <2>;
				visp_isp0_port00_sp: endpoint {
					type = "output";
					remote-endpoint = <&visp_video_0_0_1>;
				};
			};
			visp_ss_005vcap_visp_ss_0: port@5 {
				reg = <5>;
			};
			port06: port@6 {
				reg = <6>;
				visp_isp0_port01_mp: endpoint {
					type = "output";
					remote-endpoint = <&visp_video_0_1_0>;
				};
			};
			port07: port@7 {
				reg = <7>;
				visp_isp0_port01_sp: endpoint {
					type = "output";
					remote-endpoint = <&visp_video_0_1_1>;
				};
			};
			visp_ss_0010vcap_visp_ss_0: port@10 {
				reg = <10>;
			};
			port011: port@11 {
				reg = <11>;
				visp_isp0_port02_mp: endpoint {
					type = "output";
					remote-endpoint = <&visp_video_0_2_0>;
				};
			};
			port012: port@12 {
				reg = <12>;
				visp_isp0_port02_sp: endpoint {
					type = "output";
					remote-endpoint = <&visp_video_0_2_1>;
				};
			};
			visp_ss_0015vcap_visp_ss_0: port@15 {
				reg = <15>;
			};
			port016: port@16 {
				reg = <16>;
				visp_isp0_port03_mp: endpoint {
					type = "output";
					remote-endpoint = <&visp_video_0_3_0>;
				};
			};
			port017: port@17 {
				reg = <17>;
				visp_isp0_port03_sp: endpoint {
					type = "output";
					remote-endpoint = <&visp_video_0_3_1>;
				};
			};
		};
	};
	visp_video_0: visp_video_0 {
		compatible = "xlnx,visp-video";
		id = <0>;
		vcap_ports00: ports {
			#address-cells = <1>;
			#size-cells = <0>;
			vport01: port@0 {
				reg = <0>;
				visp_video_0_0_0: endpoint {
					remote-endpoint = <&visp_isp0_port00_mp>;
				};
			};
			vport02: port@1 {
				reg = <1>;
				visp_video_0_0_1: endpoint {
					remote-endpoint = <&visp_isp0_port00_sp>;
				};
			};
			vport06: port@2 {
				reg = <2>;
				visp_video_0_1_0: endpoint {
					remote-endpoint = <&visp_isp0_port01_mp>;
				};
			};
			vport07: port@3 {
				reg = <3>;
				visp_video_0_1_1: endpoint {
					remote-endpoint = <&visp_isp0_port01_sp>;
				};
			};
			vport011: port@4 {
				reg = <4>;
				visp_video_0_2_0: endpoint {
					remote-endpoint = <&visp_isp0_port02_mp>;
				};
			};
			vport012: port@5 {
				reg = <5>;
				visp_video_0_2_1: endpoint {
					remote-endpoint = <&visp_isp0_port02_sp>;
				};
			};
			vport016: port@6 {
				reg = <6>;
				visp_video_0_3_0: endpoint {
					remote-endpoint = <&visp_isp0_port03_mp>;
				};
			};
			vport017: port@7 {
				reg = <7>;
				visp_video_0_3_1: endpoint {
					remote-endpoint = <&visp_isp0_port03_sp>;
				};
			};
		};
	};
	visp_ss_01: visp_ss@b0002800 {
		xlnx,iba4_ppc = <4>;
		compatible = "xlnx,visp-ss-limo-1.0";
		interrupts = <0 108 4> , <0 109 4>;
		xlnx,iba4_max-height = <2160>;
		xlnx,io_mode = "limo";
		xlnx,iba4_vcid = <0>;
		interrupt-parent = <&gic>;
		xlnx,num_streams = <1>;
		xlnx,ip-name = "visp_ss";
		reg = <0x0 0xb0002800 0x0 0x800>;
		xlnx,netfps = <60>;
		xlnx,iba4_data_format = <16>;
		xlnx,iba4_max-width = <3840>;
		isp_id = <1>;
		xlnx,iba4_frame_rate = <60>;
		xlnx,rpu = <6>;
		interrupt-names = "tile0_isp1_fusa_irq" , "tile0_isp1_isp_irq";
		xlnx,name = "visp_ss_01";
		xlnx,mem_inputs = <0>;
		ports01: ports {
			#address-cells = <1>;
			#size-cells = <0>;
			visp_ss_010vcap_visp_ss_0: port@0 {
				reg = <0>;
			};
			port11: port@1 {
				reg = <1>;
				visp_isp1_port10_mp: endpoint {
					type = "output";
					remote-endpoint = <&visp_video_1_0_0>;
				};
			};
			port12: port@2 {
				reg = <2>;
				visp_isp1_port10_sp: endpoint {
					type = "output";
					remote-endpoint = <&visp_video_1_0_1>;
				};
			};
		};
	};
	visp_video_1: visp_video_1 {
		compatible = "xlnx,visp-video";
		id = <1>;
		vcap_ports01: ports {
			#address-cells = <1>;
			#size-cells = <0>;
			vport11: port@0 {
				reg = <0>;
				visp_video_1_0_0: endpoint {
					remote-endpoint = <&visp_isp1_port10_mp>;
				};
			};
			vport12: port@1 {
				reg = <1>;
				visp_video_1_0_1: endpoint {
					remote-endpoint = <&visp_isp1_port10_sp>;
				};
			};
		};
	};
	visp_ss_12: visp_ss@b0003000 {
		xlnx,iba1_frame_rate = <15>;
		compatible = "xlnx,visp-ss-limo-1.0";
		interrupts = <0 51 4> , <0 52 4> , <0 110 4> , <0 111 4>;
		xlnx,iba2_vcid = <2>;
		xlnx,iba3_frame_rate = <15>;
		xlnx,io_mode = "limo";
		xlnx,iba0_data_format = <12>;
		xlnx,iba1_data_format = <12>;
		xlnx,iba0_max-width = <3840>;
		interrupt-parent = <&gic>;
		xlnx,num_streams = <4>;
		xlnx,iba2_data_format = <12>;
		xlnx,iba1_max-width = <3840>;
		xlnx,ip-name = "visp_ss";
		xlnx,iba3_data_format = <12>;
		xlnx,iba2_max-width = <3840>;
		xlnx,iba1_max-height = <2160>;
		reg = <0x0 0xb0003000 0x0 0x800>;
		xlnx,netfps = <60>;
		xlnx,iba3_max-width = <3840>;
		xlnx,iba0_frame_rate = <15>;
		xlnx,iba3_max-height = <2160>;
		xlnx,iba1_vcid = <1>;
		isp_id = <2>;
		xlnx,iba2_frame_rate = <15>;
		xlnx,iba3_vcid = <3>;
		xlnx,iba0_ppc = <4>;
		xlnx,iba1_ppc = <4>;
		xlnx,iba0_max-height = <2160>;
		xlnx,rpu = <7>;
		xlnx,iba2_ppc = <4>;
		interrupt-names = "tile1_isp0_fusa_irq" , "tile1_isp0_isp_irq" , "tile1_isp_isr_irq" , "tile1_isp_xmpu_interrupt";
		xlnx,iba3_ppc = <4>;
		xlnx,iba2_max-height = <2160>;
		xlnx,iba0_vcid = <0>;
		xlnx,name = "visp_ss_12";
		xlnx,mem_inputs = <0>;
		ports12: ports {
			#address-cells = <1>;
			#size-cells = <0>;
			visp_ss_120vcap_visp_ss_0: port@0 {
				reg = <0>;
				vcap_visp_ss_0vcap_hier_mipi_1_mipi_csi2_rx_subsyst_0: endpoint {
					remote-endpoint = <&mipi_csirx_outvcap_hier_mipi_1_mipi_csi2_rx_subsyst_0>;
				};
			};
			port21: port@1 {
				reg = <1>;
				visp_isp2_port20_mp: endpoint {
					type = "output";
					remote-endpoint = <&visp_video_2_0_0>;
				};
			};
			port22: port@2 {
				reg = <2>;
				visp_isp2_port20_sp: endpoint {
					type = "output";
					remote-endpoint = <&visp_video_2_0_1>;
				};
			};
			visp_ss_125vcap_visp_ss_0: port@5 {
				reg = <5>;
			};
			port26: port@6 {
				reg = <6>;
				visp_isp2_port21_mp: endpoint {
					type = "output";
					remote-endpoint = <&visp_video_2_1_0>;
				};
			};
			port27: port@7 {
				reg = <7>;
				visp_isp2_port21_sp: endpoint {
					type = "output";
					remote-endpoint = <&visp_video_2_1_1>;
				};
			};
			visp_ss_1210vcap_visp_ss_0: port@10 {
				reg = <10>;
			};
			port211: port@11 {
				reg = <11>;
				visp_isp2_port22_mp: endpoint {
					type = "output";
					remote-endpoint = <&visp_video_2_2_0>;
				};
			};
			port212: port@12 {
				reg = <12>;
				visp_isp2_port22_sp: endpoint {
					type = "output";
					remote-endpoint = <&visp_video_2_2_1>;
				};
			};
			visp_ss_1215vcap_visp_ss_0: port@15 {
				reg = <15>;
			};
			port216: port@16 {
				reg = <16>;
				visp_isp2_port23_mp: endpoint {
					type = "output";
					remote-endpoint = <&visp_video_2_3_0>;
				};
			};
			port217: port@17 {
				reg = <17>;
				visp_isp2_port23_sp: endpoint {
					type = "output";
					remote-endpoint = <&visp_video_2_3_1>;
				};
			};
		};
	};
	visp_video_2: visp_video_2 {
		compatible = "xlnx,visp-video";
		id = <2>;
		vcap_ports12: ports {
			#address-cells = <1>;
			#size-cells = <0>;
			vport21: port@0 {
				reg = <0>;
				visp_video_2_0_0: endpoint {
					remote-endpoint = <&visp_isp2_port20_mp>;
				};
			};
			vport22: port@1 {
				reg = <1>;
				visp_video_2_0_1: endpoint {
					remote-endpoint = <&visp_isp2_port20_sp>;
				};
			};
			vport26: port@2 {
				reg = <2>;
				visp_video_2_1_0: endpoint {
					remote-endpoint = <&visp_isp2_port21_mp>;
				};
			};
			vport27: port@3 {
				reg = <3>;
				visp_video_2_1_1: endpoint {
					remote-endpoint = <&visp_isp2_port21_sp>;
				};
			};
			vport211: port@4 {
				reg = <4>;
				visp_video_2_2_0: endpoint {
					remote-endpoint = <&visp_isp2_port22_mp>;
				};
			};
			vport212: port@5 {
				reg = <5>;
				visp_video_2_2_1: endpoint {
					remote-endpoint = <&visp_isp2_port22_sp>;
				};
			};
			vport216: port@6 {
				reg = <6>;
				visp_video_2_3_0: endpoint {
					remote-endpoint = <&visp_isp2_port23_mp>;
				};
			};
			vport217: port@7 {
				reg = <7>;
				visp_video_2_3_1: endpoint {
					remote-endpoint = <&visp_isp2_port23_sp>;
				};
			};
		};
	};
	visp_ss_13: visp_ss@b0003800 {
		xlnx,iba4_ppc = <4>;
		compatible = "xlnx,visp-ss-limo-1.0";
		interrupts = <0 53 4> , <0 54 4>;
		xlnx,iba4_max-height = <2160>;
		xlnx,io_mode = "limo";
		xlnx,iba4_vcid = <0>;
		interrupt-parent = <&gic>;
		xlnx,num_streams = <1>;
		xlnx,ip-name = "visp_ss";
		reg = <0x0 0xb0003800 0x0 0x800>;
		xlnx,netfps = <60>;
		xlnx,iba4_data_format = <12>;
		xlnx,iba4_max-width = <3840>;
		isp_id = <3>;
		xlnx,iba4_frame_rate = <60>;
		xlnx,rpu = <7>;
		interrupt-names = "tile1_isp1_fusa_irq" , "tile1_isp1_isp_irq";
		xlnx,name = "visp_ss_13";
		xlnx,mem_inputs = <0>;
		ports13: ports {
			#address-cells = <1>;
			#size-cells = <0>;
			visp_ss_130vcap_visp_ss_0: port@0 {
				reg = <0>;
			};
			port31: port@1 {
				reg = <1>;
				visp_isp3_port30_mp: endpoint {
					type = "output";
					remote-endpoint = <&visp_video_3_0_0>;
				};
			};
			port32: port@2 {
				reg = <2>;
				visp_isp3_port30_sp: endpoint {
					type = "output";
					remote-endpoint = <&visp_video_3_0_1>;
				};
			};
		};
	};
	visp_video_3: visp_video_3 {
		compatible = "xlnx,visp-video";
		id = <3>;
		vcap_ports13: ports {
			#address-cells = <1>;
			#size-cells = <0>;
			vport31: port@0 {
				reg = <0>;
				visp_video_3_0_0: endpoint {
					remote-endpoint = <&visp_isp3_port30_mp>;
				};
			};
			vport32: port@1 {
				reg = <1>;
				visp_video_3_0_1: endpoint {
					remote-endpoint = <&visp_isp3_port30_sp>;
				};
			};
		};
	};
	visp_ss_24: visp_ss@b0004000 {
		xlnx,iba1_frame_rate = <15>;
		compatible = "xlnx,visp-ss-limo-1.0";
		interrupts = <0 84 4> , <0 85 4> , <0 82 4> , <0 83 4>;
		xlnx,iba2_vcid = <2>;
		xlnx,iba3_frame_rate = <15>;
		xlnx,io_mode = "limo";
		xlnx,iba0_data_format = <12>;
		xlnx,iba1_data_format = <12>;
		xlnx,iba0_max-width = <3840>;
		interrupt-parent = <&gic>;
		xlnx,num_streams = <4>;
		xlnx,iba2_data_format = <12>;
		xlnx,iba1_max-width = <3840>;
		xlnx,ip-name = "visp_ss";
		xlnx,iba3_data_format = <12>;
		xlnx,iba2_max-width = <3840>;
		xlnx,iba1_max-height = <2160>;
		reg = <0x0 0xb0004000 0x0 0x800>;
		xlnx,netfps = <60>;
		xlnx,iba3_max-width = <3840>;
		xlnx,iba0_frame_rate = <15>;
		xlnx,iba3_max-height = <2160>;
		xlnx,iba1_vcid = <1>;
		isp_id = <4>;
		xlnx,iba2_frame_rate = <15>;
		xlnx,iba3_vcid = <3>;
		xlnx,iba0_ppc = <4>;
		xlnx,iba1_ppc = <4>;
		xlnx,iba0_max-height = <2160>;
		xlnx,rpu = <8>;
		xlnx,iba2_ppc = <4>;
		interrupt-names = "tile2_isp0_fusa_irq" , "tile2_isp0_isp_irq" , "tile2_isp_isr_irq" , "tile2_isp_xmpu_interrupt";
		xlnx,iba3_ppc = <4>;
		xlnx,iba2_max-height = <2160>;
		xlnx,iba0_vcid = <0>;
		xlnx,name = "visp_ss_24";
		xlnx,mem_inputs = <0>;
		ports24: ports {
			#address-cells = <1>;
			#size-cells = <0>;
			visp_ss_240vcap_visp_ss_0: port@0 {
				reg = <0>;
				vcap_visp_ss_0vcap_hier_mipi_2_mipi_csi2_rx_subsyst_0: endpoint {
					remote-endpoint = <&mipi_csirx_outvcap_hier_mipi_2_mipi_csi2_rx_subsyst_0>;
				};
			};
			port41: port@1 {
				reg = <1>;
				visp_isp4_port40_mp: endpoint {
					type = "output";
					remote-endpoint = <&visp_video_4_0_0>;
				};
			};
			port42: port@2 {
				reg = <2>;
				visp_isp4_port40_sp: endpoint {
					type = "output";
					remote-endpoint = <&visp_video_4_0_1>;
				};
			};
			visp_ss_245vcap_visp_ss_0: port@5 {
				reg = <5>;
			};
			port46: port@6 {
				reg = <6>;
				visp_isp4_port41_mp: endpoint {
					type = "output";
					remote-endpoint = <&visp_video_4_1_0>;
				};
			};
			port47: port@7 {
				reg = <7>;
				visp_isp4_port41_sp: endpoint {
					type = "output";
					remote-endpoint = <&visp_video_4_1_1>;
				};
			};
			visp_ss_2410vcap_visp_ss_0: port@10 {
				reg = <10>;
			};
			port411: port@11 {
				reg = <11>;
				visp_isp4_port42_mp: endpoint {
					type = "output";
					remote-endpoint = <&visp_video_4_2_0>;
				};
			};
			port412: port@12 {
				reg = <12>;
				visp_isp4_port42_sp: endpoint {
					type = "output";
					remote-endpoint = <&visp_video_4_2_1>;
				};
			};
			visp_ss_2415vcap_visp_ss_0: port@15 {
				reg = <15>;
			};
			port416: port@16 {
				reg = <16>;
				visp_isp4_port43_mp: endpoint {
					type = "output";
					remote-endpoint = <&visp_video_4_3_0>;
				};
			};
			port417: port@17 {
				reg = <17>;
				visp_isp4_port43_sp: endpoint {
					type = "output";
					remote-endpoint = <&visp_video_4_3_1>;
				};
			};
		};
	};
	visp_video_4: visp_video_4 {
		compatible = "xlnx,visp-video";
		id = <4>;
		vcap_ports24: ports {
			#address-cells = <1>;
			#size-cells = <0>;
			vport41: port@0 {
				reg = <0>;
				visp_video_4_0_0: endpoint {
					remote-endpoint = <&visp_isp4_port40_mp>;
				};
			};
			vport42: port@1 {
				reg = <1>;
				visp_video_4_0_1: endpoint {
					remote-endpoint = <&visp_isp4_port40_sp>;
				};
			};
			vport46: port@2 {
				reg = <2>;
				visp_video_4_1_0: endpoint {
					remote-endpoint = <&visp_isp4_port41_mp>;
				};
			};
			vport47: port@3 {
				reg = <3>;
				visp_video_4_1_1: endpoint {
					remote-endpoint = <&visp_isp4_port41_sp>;
				};
			};
			vport411: port@4 {
				reg = <4>;
				visp_video_4_2_0: endpoint {
					remote-endpoint = <&visp_isp4_port42_mp>;
				};
			};
			vport412: port@5 {
				reg = <5>;
				visp_video_4_2_1: endpoint {
					remote-endpoint = <&visp_isp4_port42_sp>;
				};
			};
			vport416: port@6 {
				reg = <6>;
				visp_video_4_3_0: endpoint {
					remote-endpoint = <&visp_isp4_port43_mp>;
				};
			};
			vport417: port@7 {
				reg = <7>;
				visp_video_4_3_1: endpoint {
					remote-endpoint = <&visp_isp4_port43_sp>;
				};
			};
		};
	};
	visp_ss_25: visp_ss@b0004800 {
		xlnx,iba4_ppc = <4>;
		compatible = "xlnx,visp-ss-limo-1.0";
		interrupts = <0 86 4> , <0 87 4>;
		xlnx,iba4_max-height = <2160>;
		xlnx,io_mode = "limo";
		xlnx,iba4_vcid = <0>;
		interrupt-parent = <&gic>;
		xlnx,num_streams = <1>;
		xlnx,ip-name = "visp_ss";
		reg = <0x0 0xb0004800 0x0 0x800>;
		xlnx,netfps = <60>;
		xlnx,iba4_data_format = <16>;
		xlnx,iba4_max-width = <3840>;
		isp_id = <5>;
		xlnx,iba4_frame_rate = <60>;
		xlnx,rpu = <8>;
		interrupt-names = "tile2_isp1_fusa_irq" , "tile2_isp1_isp_irq";
		xlnx,name = "visp_ss_25";
		xlnx,mem_inputs = <0>;
		ports25: ports {
			#address-cells = <1>;
			#size-cells = <0>;
			visp_ss_250vcap_visp_ss_0: port@0 {
				reg = <0>;
			};
			port51: port@1 {
				reg = <1>;
				visp_isp5_port50_mp: endpoint {
					type = "output";
					remote-endpoint = <&visp_video_5_0_0>;
				};
			};
			port52: port@2 {
				reg = <2>;
				visp_isp5_port50_sp: endpoint {
					type = "output";
					remote-endpoint = <&visp_video_5_0_1>;
				};
			};
		};
	};
	visp_video_5: visp_video_5 {
		compatible = "xlnx,visp-video";
		id = <5>;
		vcap_ports25: ports {
			#address-cells = <1>;
			#size-cells = <0>;
			vport51: port@0 {
				reg = <0>;
				visp_video_5_0_0: endpoint {
					remote-endpoint = <&visp_isp5_port50_mp>;
				};
			};
			vport52: port@1 {
				reg = <1>;
				visp_video_5_0_1: endpoint {
					remote-endpoint = <&visp_isp5_port50_sp>;
				};
			};
		};
	};
	visp_mbox_rpu_8: visp_mbox_rpu_8 {
		compatible = "xlnx,mbox";
		mboxes = <&ipi_6_to_ipi_5_nobuf 0x0>, <&ipi_6_to_ipi_5_nobuf 0x1>;
		mbox-names = "tx" , "rx";
		rpu_id = <8>;
	};
	visp_mbox_rpu_6: visp_mbox_rpu_6 {
		compatible = "xlnx,mbox";
		mboxes = <&ipi_5_to_ipi_3_nobuf 0x0>, <&ipi_5_to_ipi_3_nobuf 0x1>;
		mbox-names = "tx" , "rx";
		rpu_id = <6>;
	};
	visp_mbox_rpu_7: visp_mbox_rpu_7 {
		compatible = "xlnx,mbox";
		mboxes = <&ipi_5_to_ipi_4_nobuf 0x0>, <&ipi_5_to_ipi_4_nobuf 0x1>;
		mbox-names = "tx" , "rx";
		rpu_id = <7>;
	};
	encoder: ale2xx@e8040000 {
		interrupt-parent = <&axi_intc_0>;
		interrupts = <2 6 2>;
		compatible = "al,ale2xx";
		clock-names = "mcu";
		al,devicename = "al_e2xx";
		reg = <0x0 0xe8040000 0x0 0x80000 0x0 0x8000000 0x0 0x8000000>;
		xlnx,mcu-clk = <950>;
		reg-names = "regs" , "apb";
	};
	decoder: ald3xx@e8080000 {
		interrupt-parent = <&axi_intc_0>;
		interrupts = <7 2 8>;
		compatible = "al,ald3xx";
		clock-names = "mcu";
		al,devicename = "al_d3xx";
		reg = <0x0 0xe8080000 0x0 0x80000 0x0 0x00000000 0x0 0x08000000>;
		xlnx,mcu-clk = <918>;
		reg-names = "regs" , "apb";
	};
	zyxclmm_drm {
		compatible = "xlnx,zocl-versal";
		interrupts-extended = <&axi_intc_0 0 4>, <&axi_intc_0 1 4>, <&axi_intc_0 2 4>, <&axi_intc_0 3 4>, <&axi_intc_0 4 4>, <&axi_intc_0 5 4>, <&axi_intc_0 6 4>, <&axi_intc_0 7 4>, <&axi_intc_0 8 4>, <&axi_intc_0 9 4>, <&axi_intc_0 10 4>, <&axi_intc_0 11 4>, <&axi_intc_0 12 4>, <&axi_intc_0 13 4>, <&axi_intc_0 14 4>, <&axi_intc_0 15 4>, <&axi_intc_0 16 4>, <&axi_intc_0 17 4>, <&axi_intc_0 18 4>, <&axi_intc_0 19 4>, <&axi_intc_0 20 4>, <&axi_intc_0 21 4>, <&axi_intc_0 22 4>, <&axi_intc_0 23 4>, <&axi_intc_0 24 4>, <&axi_intc_0 25 4>, <&axi_intc_0 26 4>, <&axi_intc_0 27 4>, <&axi_intc_0 28 4>, <&axi_intc_0 29 4>, <&axi_intc_0 30 4>, <&axi_intc_0 31 4>;
	};
};
